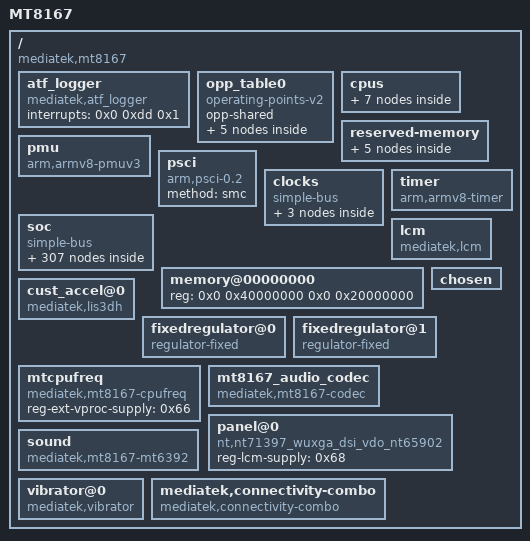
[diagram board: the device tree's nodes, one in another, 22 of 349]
/dts-v1/;

/ {
	model = "MT8167";
	compatible = "mediatek,mt8167";
	interrupt-parent = <0x1>;
	#address-cells = <0x2>;
	#size-cells = <0x2>;

	atf_logger {
		compatible = "mediatek,atf_logger";
		interrupts = <0x0 0xdd 0x1>;
	};

	opp_table0 {
		compatible = "operating-points-v2";
		opp-shared;
		linux,phandle = <0x7>;
		phandle = <0x7>;

		opp00 {
			opp-hz = <0x0 0x23a4c180>;
			opp-microvolt = <0x118c30>;
		};

		opp01 {
			opp-hz = <0x0 0x2c8df1e0>;
			opp-microvolt = <0x118c30>;
		};

		opp02 {
			opp-hz = <0x0 0x3dfd2400>;
			opp-microvolt = <0x124f80>;
		};

		opp03 {
			opp-hz = <0x0 0x47498300>;
			opp-microvolt = <0x1312d0>;
		};

		opp04 {
			opp-hz = <0x0 0x4d7c6d00>;
			opp-microvolt = <0x13d620>;
		};
	};

	cpus {
		#address-cells = <0x1>;
		#size-cells = <0x0>;

		cpu@0 {
			device_type = "cpu";
			compatible = "arm,cortex-a53";
			reg = <0x0>;
			enable-method = "psci";
			cpu-idle-states = <0x2 0x2 0x3 0x3 0x3>;
			clocks = <0x4 0x0 0x5 0x8 0x6 0x0>;
			clock-names = "cpu", "intermediate", "armpll";
			operating-points-v2 = <0x7>;
			clock-frequency = "M|m";
			proc-supply = <0x8>;
			linux,phandle = <0x9>;
			phandle = <0x9>;
		};

		cpu@1 {
			device_type = "cpu";
			compatible = "arm,cortex-a53";
			reg = <0x1>;
			enable-method = "psci";
			cpu-idle-states = <0x2 0x2 0x3 0x3 0x3>;
			clocks = <0x4 0x0 0x5 0x8 0x6 0x0>;
			clock-names = "cpu", "intermediate", "armpll";
			operating-points-v2 = <0x7>;
			clock-frequency = "M|m";
			proc-supply = <0x8>;
			linux,phandle = <0xa>;
			phandle = <0xa>;
		};

		cpu@2 {
			device_type = "cpu";
			compatible = "arm,cortex-a53";
			reg = <0x2>;
			enable-method = "psci";
			cpu-idle-states = <0x2 0x2 0x3 0x3 0x3>;
			clocks = <0x4 0x0 0x5 0x8 0x6 0x0>;
			clock-names = "cpu", "intermediate", "armpll";
			operating-points-v2 = <0x7>;
			clock-frequency = "M|m";
			proc-supply = <0x8>;
			linux,phandle = <0xb>;
			phandle = <0xb>;
		};

		cpu@3 {
			device_type = "cpu";
			compatible = "arm,cortex-a53";
			reg = <0x3>;
			enable-method = "psci";
			cpu-idle-states = <0x2 0x2 0x3 0x3 0x3>;
			clocks = <0x4 0x0 0x5 0x8 0x6 0x0>;
			clock-names = "cpu", "intermediate", "armpll";
			operating-points-v2 = <0x7>;
			clock-frequency = "M|m";
			proc-supply = <0x8>;
			linux,phandle = <0xc>;
			phandle = <0xc>;
		};

		idle-states {
			entry-method = "arm,psci";

			cpu-sleep-0-0 {
				compatible = "arm,idle-state";
				arm,psci-suspend-param = <0x10000>;
				entry-latency-us = <0x258>;
				exit-latency-us = <0x258>;
				min-residency-us = <0x4b0>;
				linux,phandle = <0x3>;
				phandle = <0x3>;
			};

			cluster-sleep-0 {
				compatible = "arm,idle-state";
				arm,psci-suspend-param = <0x2010000>;
				entry-latency-us = <0x320>;
				exit-latency-us = <0x3e8>;
				min-residency-us = <0x7d0>;
				linux,phandle = <0x2>;
				phandle = <0x2>;
			};
		};
	};

	reserved-memory {
		#address-cells = <0x2>;
		#size-cells = <0x2>;
		ranges;

		atf-reserved-memory@43000000 {
			compatible = "mediatek,mt8167-atf-reserved-memory";
			no-map;
			reg = <0x0 0x43000000 0x0 0x30000>;
		};

		ram_console-reserved-memory@44400000 {
			compatible = "mediatek,ram_console";
			reg = <0x0 0x44400000 0x0 0x10000>;
		};

		pstore-reserved-memory@44410000 {
			compatible = "mediatek,pstore";
			reg = <0x0 0x44410000 0x0 0xe0000>;
		};

		minirdump-reserved-memory@444f0000 {
			compatible = "mediatek,minirdump";
			reg = <0x0 0x444f0000 0x0 0x10000>;
		};

		consys-reserve-memory {
			compatible = "mediatek,consys-reserve-memory";
			no-map;
			size = <0x0 0x200000>;
			alignment = <0x0 0x200000>;
		};
	};

	pmu {
		compatible = "arm,armv8-pmuv3";
		interrupts = <0x0 0x4 0x8 0x0 0x5 0x8 0x0 0x6 0x8 0x0 0x7 0x8>;
		interrupt-affinity = <0x9 0xa 0xb 0xc>;
	};

	psci {
		compatible = "arm,psci-0.2";
		method = "smc";
	};

	clocks {
		#address-cells = <0x2>;
		#size-cells = <0x2>;
		compatible = "simple-bus";
		ranges;

		clk26m {
			compatible = "fixed-clock";
			#clock-cells = <0x0>;
			clock-frequency = <0x18cba80>;
		};

		clk32k {
			compatible = "fixed-clock";
			#clock-cells = <0x0>;
			clock-frequency = <0x7d00>;
			linux,phandle = <0xe>;
			phandle = <0xe>;
		};

		dummy26m {
			compatible = "fixed-clock";
			clock-frequency = <0x18cba80>;
			#clock-cells = <0x0>;
		};
	};

	timer {
		compatible = "arm,armv8-timer";
		interrupt-parent = <0xd>;
		interrupts = <0x1 0xd 0xf08 0x1 0xe 0xf08 0x1 0xb 0xf08 0x1 0xa 0xf08>;
		clock-frequency = <0xc65d40>;
	};

	soc {
		#address-cells = <0x2>;
		#size-cells = <0x2>;
		compatible = "simple-bus";
		ranges;

		chipid@08000000 {
			compatible = "mediatek,chipid";
			reg = <0x0 0x8000000 0x0 0x4 0x0 0x8000004 0x0 0x4 0x0 0x8000008 0x0 0x4 0x0 0x800000c 0x0 0x4>;
		};

		topckgen@10000000 {
			compatible = "mediatek,mt8167-topckgen", "syscon";
			reg = <0x0 0x10000000 0x0 0x1000>;
			#clock-cells = <0x1>;
			linux,phandle = <0x5>;
			phandle = <0x5>;
		};

		infracfg@10001000 {
			compatible = "mediatek,mt8167-infracfg", "syscon";
			reg = <0x0 0x10001000 0x0 0x1000>;
			#clock-cells = <0x1>;
			linux,phandle = <0x4>;
			phandle = <0x4>;
		};

		btcvsd@10001000 {
			compatible = "mediatek,audio_bt_cvsd";
			offset = <0xc00 0x2 0xfd0 0xfd4 0xfd8>;
			reg = <0x0 0x10001000 0x0 0x1000 0x0 0x18000000 0x0 0x10000 0x0 0x18080000 0x0 0x8000>;
			interrupts = <0x0 0xc2 0x8>;
		};

		mt_soc_btcvsd_rx_pcm@10001000 {
			compatible = "mediatek,mt_soc_btcvsd_rx_pcm";
		};

		mt_soc_btcvsd_tx_pcm@10001000 {
			compatible = "mediatek,mt_soc_btcvsd_tx_pcm";
		};

		syscfg_pctl_a@10005000 {
			compatible = "mediatek,mt8167-pctl-a-syscfg", "syscon";
			reg = <0x0 0x10005000 0x0 0x1000>;
			linux,phandle = <0xf>;
			phandle = <0xf>;
		};

		toprgu@10007000 {
			compatible = "mediatek,mt8167-wdt", "mediatek,mt6589-wdt";
			reg = <0x0 0x10007000 0x0 0x1000>;
			interrupts = <0x0 0xc6 0x2>;
			#reset-cells = <0x1>;
			linux,phandle = <0x54>;
			phandle = <0x54>;
		};

		timer@10008000 {
			compatible = "mediatek,mt8167-timer", "mediatek,mt6577-timer";
			reg = <0x0 0x10008000 0x0 0x1000>;
			interrupts = <0x0 0x84 0x8>;
			clocks = <0x5 0x32 0xe 0x5 0x5a>;
			clock-names = "clk13m", "clk32k", "bus";
		};

		pinctrl@10005000 {
			compatible = "mediatek,mt8167-pinctrl";
			reg = <0x0 0x1000b000 0x0 0x1000>;
			mediatek,pctl-regmap = <0xf>;
			pins-are-numbered;
			gpio-controller;
			#gpio-cells = <0x2>;
			interrupt-controller;
			#interrupt-cells = <0x2>;
			interrupts = <0x0 0x86 0x4>;
			pinctrl-names = "default";
			pinctrl-0 = <0x10>;
			linux,phandle = <0x12>;
			phandle = <0x12>;

			uart0gpiodefault {
				linux,phandle = <0x17>;
				phandle = <0x17>;
			};

			uart0_rx_set {
				linux,phandle = <0x18>;
				phandle = <0x18>;

				pins_cmd_dat {
					pinmux = <0x3e01>;
				};
			};

			uart0_rx_clear {
				linux,phandle = <0x19>;
				phandle = <0x19>;

				pins_cmd_dat {
					pinmux = <0x3e00>;
					slew-rate = <0x1>;
					output-high;
				};
			};

			uart0_tx_set {
				linux,phandle = <0x1a>;
				phandle = <0x1a>;

				pins_cmd_dat {
					pinmux = <0x3f01>;
				};
			};

			uart0_tx_clear {
				linux,phandle = <0x1b>;
				phandle = <0x1b>;

				pins_cmd_dat {
					pinmux = <0x3f00>;
					slew-rate = <0x1>;
					output-high;
				};
			};

			uart1gpiodefault {
				linux,phandle = <0x1c>;
				phandle = <0x1c>;
			};

			uart1_rx_set {
				linux,phandle = <0x1d>;
				phandle = <0x1d>;

				pins_cmd_dat {
					pinmux = <0x4001>;
				};
			};

			uart1_rx_clear {
				linux,phandle = <0x1e>;
				phandle = <0x1e>;

				pins_cmd_dat {
					pinmux = <0x4000>;
					slew-rate = <0x1>;
					output-high;
				};
			};

			uart1_tx_set {
				linux,phandle = <0x1f>;
				phandle = <0x1f>;

				pins_cmd_dat {
					pinmux = <0x4101>;
				};
			};

			uart1_tx_clear {
				linux,phandle = <0x20>;
				phandle = <0x20>;

				pins_cmd_dat {
					pinmux = <0x4100>;
					slew-rate = <0x1>;
					output-high;
				};
			};

			uart2gpiodefault {
				linux,phandle = <0x21>;
				phandle = <0x21>;
			};

			uart2_rx_set {
				linux,phandle = <0x22>;
				phandle = <0x22>;

				pins_cmd_dat {
					pinmux = <0x2201>;
				};
			};

			uart2_rx_clear {
				linux,phandle = <0x23>;
				phandle = <0x23>;

				pins_cmd_dat {
					pinmux = <0x2200>;
					slew-rate = <0x1>;
					output-high;
				};
			};

			uart2_tx_set {
				linux,phandle = <0x24>;
				phandle = <0x24>;

				pins_cmd_dat {
					pins = <0x2301>;
				};
			};

			uart2_tx_clear {
				linux,phandle = <0x25>;
				phandle = <0x25>;

				pins_cmd_dat {
					pinmux = <0x2300>;
					slew-rate = <0x1>;
					output-high;
				};
			};

			pinconf_default {
				linux,phandle = <0x10>;
				phandle = <0x10>;
			};

			audiodefault {
				linux,phandle = <0x69>;
				phandle = <0x69>;

				pins_extamp_default {
					pins = <0x1700>;
					slew-rate = <0x1>;
					output-low;
				};
			};

			audexampon {
				linux,phandle = <0x6a>;
				phandle = <0x6a>;

				pins_cmd_dat {
					pins = <0x1700>;
					slew-rate = <0x1>;
					output-high;
				};
			};

			audexampoff {
				linux,phandle = <0x6b>;
				phandle = <0x6b>;

				pins_cmd_dat {
					pins = <0x1700>;
					slew-rate = <0x1>;
					output-low;
				};
			};

			audi2s1mode0 {
			};

			audi2s1mode1 {
			};

			pmicclkmode0 {
			};

			pmicclkmode1 {
			};

			camdefault {
				linux,phandle = <0x47>;
				phandle = <0x47>;

				pins_cmd_dat {
					pinmux = <0x5401 0x5501 0x5601 0x5701 0x5801 0x5901 0x5a01 0x5b01 0x5c01 0x5d01>;
				};
			};

			cam_pin_gpio90 {
				linux,phandle = <0x4a>;
				phandle = <0x4a>;
			};

			cam_pin_gpio91 {
				linux,phandle = <0x4b>;
				phandle = <0x4b>;
			};

			cam_pin_gpio92 {
				linux,phandle = <0x4c>;
				phandle = <0x4c>;
			};

			cam_pin_gpio93 {
				linux,phandle = <0x4d>;
				phandle = <0x4d>;
			};

			cam_pin_gpio94 {
				linux,phandle = <0x4e>;
				phandle = <0x4e>;
			};

			cam_pin_gpio95 {
				linux,phandle = <0x4f>;
				phandle = <0x4f>;
			};

			cam_pin_gpio96 {
				linux,phandle = <0x50>;
				phandle = <0x50>;
			};

			cam_pin_gpio97 {
				linux,phandle = <0x51>;
				phandle = <0x51>;
			};

			cam_pin_gpio98 {
				linux,phandle = <0x52>;
				phandle = <0x52>;
			};

			cam_pin_gpio99 {
				linux,phandle = <0x53>;
				phandle = <0x53>;
			};

			cam_pin_mclk {
				linux,phandle = <0x48>;
				phandle = <0x48>;

				pins_cmd_dat {
					pins = <0x6601>;
				};
			};

			cam_pin_pclk {
				linux,phandle = <0x49>;
				phandle = <0x49>;
			};

			default {
				linux,phandle = <0x55>;
				phandle = <0x55>;
			};

			eint0default {
				linux,phandle = <0x5c>;
				phandle = <0x5c>;

				pins_cmd_dat {
					pins = <0x6400>;
					slew-rate = <0x0>;
					bias-disable;
				};
			};

			eint@0 {
				linux,phandle = <0x5d>;
				phandle = <0x5d>;

				pins_cmd_dat {
					pins = <0x6400>;
					slew-rate = <0x0>;
					bias-disable;
				};
			};

			eintoutput0 {
				linux,phandle = <0x5e>;
				phandle = <0x5e>;

				pins_cmd_dat {
					pins = <0x6400>;
					slew-rate = <0x1>;
					output-low;
				};
			};

			eintoutput1 {
				linux,phandle = <0x5f>;
				phandle = <0x5f>;

				pins_cmd_dat {
					pins = <0x6400>;
					slew-rate = <0x1>;
					output-high;
				};
			};

			rstoutput0 {
				linux,phandle = <0x60>;
				phandle = <0x60>;

				pins_cmd_dat {
					pins = <0x6500>;
					slew-rate = <0x1>;
					output-low;
				};
			};

			rstoutput1 {
				linux,phandle = <0x61>;
				phandle = <0x61>;

				pins_cmd_dat {
					pins = <0x6500>;
					slew-rate = <0x1>;
					output-high;
				};
			};

			hwen_high {
				linux,phandle = <0x63>;
				phandle = <0x63>;
			};

			hwen_low {
				linux,phandle = <0x64>;
				phandle = <0x64>;
			};

			gpslna@0 {
				linux,phandle = <0x56>;
				phandle = <0x56>;
			};

			gpslna@1 {
				linux,phandle = <0x57>;
				phandle = <0x57>;
			};

			gpslna@2 {
				linux,phandle = <0x58>;
				phandle = <0x58>;
			};

			hdmi_pins_default {
				linux,phandle = <0x3e>;
				phandle = <0x3e>;
			};

			hdmi_pins_hpd {
				linux,phandle = <0x3f>;
				phandle = <0x3f>;
			};

			i2c0@0 {
				linux,phandle = <0x26>;
				phandle = <0x26>;

				pins1 {
					pinmux = <0x3a01 0x3b01>;
					bias-disable;
				};
			};

			i2c1@0 {
				linux,phandle = <0x27>;
				phandle = <0x27>;

				pins1 {
					pinmux = <0x3401 0x3501>;
					bias-disable;
				};
			};

			i2c2@0 {
				linux,phandle = <0x28>;
				phandle = <0x28>;

				pins1 {
					pinmux = <0x3c01 0x3d01>;
					bias-disable;
				};
			};

			mmc0default {
				linux,phandle = <0x31>;
				phandle = <0x31>;

				pins_cmd_dat {
					pinmux = <0x7801 0x7701 0x7601 0x7501 0x7101 0x7001 0x6f01 0x6e01 0x7301>;
					input-enable;
					bias-pull-up;
				};

				pins_clk {
					pinmux = <0x7401>;
					bias-pull-down;
				};

				pins_rst {
					pinmux = <0x7201>;
					bias-pull-up;
				};
			};

			mmc0@0 {
				linux,phandle = <0x32>;
				phandle = <0x32>;

				pins_cmd_dat {
					pinmux = <0x7801 0x7701 0x7601 0x7501 0x7101 0x7001 0x6f01 0x6e01 0x7301>;
					input-enable;
					drive-strength = <0x6>;
					bias-pull-up = <0x65>;
				};

				pins_clk {
					pinmux = <0x7401>;
					drive-strength = <0x8>;
					bias-pull-down = <0x66>;
				};

				pins_rst {
					pinmux = <0x7201>;
					bias-pull-up;
				};
			};

			mmc1default {
				linux,phandle = <0x35>;
				phandle = <0x35>;

				pins_cmd_dat {
					pinmux = <0x6a01 0x6b01 0x6c01 0x6d01 0x6801>;
					input-enable;
					drive-strength = <0x6>;
					bias-pull-up = <0x65>;
				};

				pins_clk {
					pinmux = <0x6901>;
					drive-strength = <0x6>;
					bias-pull-down = <0x66>;
				};

				pins_insert {
					pinmux = <0x1400>;
					bias-pull-up;
				};
			};

			mmc1@0 {
				linux,phandle = <0x36>;
				phandle = <0x36>;

				pins_cmd_dat {
					pinmux = <0x6a01 0x6b01 0x6c01 0x6d01 0x6801>;
					input-enable;
					drive-strength = <0x6>;
					bias-pull-up = <0x65>;
				};

				pins_clk {
					pinmux = <0x6901>;
					drive-strength = <0x8>;
					bias-pull-down = <0x66>;
				};
			};

			mmc2default {
				linux,phandle = <0x39>;
				phandle = <0x39>;

				pins_cmd_dat {
					pinmux = <0x4601 0x4701 0x4801 0x4901 0x4401>;
					input-enable;
					drive-strength = <0x8>;
					bias-pull-up = <0x66>;
				};

				pins_clk {
					pinmux = <0x4501>;
					drive-strength = <0x8>;
					bias-pull-down = <0x66>;
				};
			};

			cfg_pmu_en_pull_dis {
				linux,phandle = <0x6c>;
				phandle = <0x6c>;

				combo_pins {
					pins = <0x200>;
					bias-disable;
				};
			};

			cfg_pmu_en_in_pulldown {
				linux,phandle = <0x6d>;
				phandle = <0x6d>;

				combo_pins {
					pins = <0x200>;
					bias-pull-down;
				};
			};

			cfg_rst_pull_dis {
				linux,phandle = <0x6e>;
				phandle = <0x6e>;

				combo_pins {
					pins = <0x700>;
					bias-disable;
				};
			};

			cfg_wifi_eint_in_pull_dis {
				linux,phandle = <0x6f>;
				phandle = <0x6f>;

				combo_pins {
					pins = <0x500>;
					slew-rate = <0x0>;
					bias-disable;
				};
			};

			cfg_wifi_eint_in_pullup {
				linux,phandle = <0x70>;
				phandle = <0x70>;

				combo_pins {
					pins = <0x500>;
					slew-rate = <0x0>;
					bias-pull-up = <0x0>;
				};
			};

			cfg_pcm_daiclk_pull_dis {
				linux,phandle = <0x71>;
				phandle = <0x71>;

				combo_pins {
					pins = <0x2401>;
					bias-disable;
				};
			};

			cfg_pcm_daipcmin_pull_dis {
				linux,phandle = <0x72>;
				phandle = <0x72>;

				combo_pins {
					pins = <0x2601>;
					bias-disable;
				};
			};

			cfg_pcm_daipcmout_pull_dis {
				linux,phandle = <0x73>;
				phandle = <0x73>;

				combo_pins {
					pins = <0x2701>;
					bias-disable;
				};
			};

			cfg_pcm_daisync_pull_dis {
				linux,phandle = <0x74>;
				phandle = <0x74>;

				combo_pins {
					pins = <0x2501>;
					bias-disable;
				};
			};

			cfg_gps_lna_pull_dis {
				linux,phandle = <0x75>;
				phandle = <0x75>;

				combo_pins {
					pins = <0x300>;
					bias-disable;
				};
			};

			drvvbus_init {
				linux,phandle = <0x2c>;
				phandle = <0x2c>;

				pins_cmd_dat {
					pins = <0x4400>;
					output-low;
				};
			};

			drvvbus_high {
				linux,phandle = <0x2e>;
				phandle = <0x2e>;

				pins_cmd_dat {
					pins = <0x4400>;
					slew-rate = <0x1>;
					output-high;
				};
			};

			drvvbus_low {
				linux,phandle = <0x2d>;
				phandle = <0x2d>;

				pins_cmd_dat {
					pins = <0x4400>;
					slew-rate = <0x1>;
					output-low;
				};
			};

			iddig_irq_init {
				linux,phandle = <0x2b>;
				phandle = <0x2b>;

				pins_cmd_dat {
					pins = <0x2902>;
					slew-rate = <0x0>;
					bias-pull-up = <0x0>;
				};
			};

			vbus_init {
				linux,phandle = <0x3a>;
				phandle = <0x3a>;

				pins_cmd_dat {
					pins = <0x1800>;
					output-high;
				};
			};

			vbus_high {
				linux,phandle = <0x3c>;
				phandle = <0x3c>;

				pins_cmd_dat {
					pins = <0x1800>;
					slew-rate = <0x1>;
					output-high;
				};
			};

			vbus_low {
				linux,phandle = <0x3b>;
				phandle = <0x3b>;

				pins_cmd_dat {
					pins = <0x1800>;
					slew-rate = <0x1>;
					output-low;
				};
			};

			iddig_irq {
				linux,phandle = <0x3d>;
				phandle = <0x3d>;

				pins_cmd_dat {
					pins = <0x2800>;
					slew-rate = <0x0>;
					bias-pull-up = <0x0>;
				};
			};
		};

		dramco@10207000 {
			compatible = "mediatek,mt8167-dramco";
			reg = <0x0 0x10207000 0x0 0x1000>;
		};

		scpsys@10006000 {
			compatible = "mediatek,mt8167-scpsys", "syscon";
			#power-domain-cells = <0x1>;
			reg = <0x0 0x10006000 0x0 0x1000>;
			interrupts = <0x0 0x80 0x8 0x0 0x81 0x8 0x0 0x82 0x8 0x0 0x83 0x8>;
			infracfg = <0x4>;
			clocks = <0x5 0x82 0x5 0x83 0x5 0x42 0x5 0x7f>;
			clock-names = "axi_mfg", "mfg", "mm", "vdec";
			mediatek,pwrap-regmap = <0x11>;
			linux,phandle = <0x30>;
			phandle = <0x30>;
		};

		hacc@1000a000 {
			compatible = "mediatek,hacc";
			reg = <0x0 0x1000a000 0x0 0x1000>;
			clocks = <0x5 0x57 0x5 0x66>;
			clock-names = "main", "second";
		};

		pwrap@1000f000 {
			compatible = "mediatek,mt8167-pwrap";
			reg = <0x0 0x1000f000 0x0 0x1000>;
			reg-names = "pwrap";
			interrupts = <0x0 0xcc 0x8>;
			clocks = <0x5 0x5e 0x5 0x56>;
			clock-names = "spi", "wrap";
			status = "okay";
			linux,phandle = <0x11>;
			phandle = <0x11>;

			mt6392 {
				compatible = "mediatek,mt6392";
				mediatek,system-power-controller;
				interrupt-parent = <0x12>;
				interrupts = <0x1c 0x4>;
				interrupt-controller;
				#interrupt-cells = <0x2>;
				linux,phandle = <0x62>;
				phandle = <0x62>;

				mt6392keys {
					compatible = "mediatek,mt6392-keys";
					mediatek,pwrkey-code = <0x74>;
					mediatek,homekey-code = <0x0>;
					mediatek,long-press-mode = <0x1>;
					mediatek,long-press-duration = <0x3>;
				};

				mt6392pmic {
					compatible = "mediatek,mt6392-pmic";
				};

				mt6392regulator {
					compatible = "mediatek,mt6392-regulator";

					buck_vproc {
						regulator-name = "vproc";
						regulator-min-microvolt = <0xaae60>;
						regulator-max-microvolt = <0x149970>;
						regulator-ramp-delay = <0x30d4>;
						regulator-always-on;
						regulator-boot-on;
						linux,phandle = <0x8>;
						phandle = <0x8>;
					};

					buck_vsys {
						regulator-name = "vsys";
						regulator-min-microvolt = <0x155cc0>;
						regulator-max-microvolt = <0x2d95ec>;
						regulator-ramp-delay = <0x61a8>;
						regulator-always-on;
						regulator-boot-on;
					};

					buck_vcore {
						regulator-name = "vcore";
						regulator-min-microvolt = <0xaae60>;
						regulator-max-microvolt = <0x149970>;
						regulator-ramp-delay = <0x30d4>;
						regulator-always-on;
						regulator-boot-on;
						linux,phandle = <0x2a>;
						phandle = <0x2a>;
					};

					ldo_vxo22 {
						regulator-name = "vxo22";
						regulator-min-microvolt = <0x2191c0>;
						regulator-max-microvolt = <0x2191c0>;
						regulator-enable-ramp-delay = <0x6e>;
						regulator-always-on;
						regulator-boot-on;
					};

					ldo_vaud22 {
						regulator-name = "vaud22";
						regulator-min-microvolt = <0x1b7740>;
						regulator-max-microvolt = <0x2191c0>;
						regulator-enable-ramp-delay = <0x108>;
						regulator-always-on;
						regulator-boot-on;
					};

					ldo_vcama {
						regulator-name = "vcama";
						regulator-min-microvolt = <0x2ab980>;
						regulator-max-microvolt = <0x2ab980>;
						regulator-enable-ramp-delay = <0x108>;
						linux,phandle = <0x43>;
						phandle = <0x43>;
					};

					ldo_vaud28 {
						regulator-name = "vaud28";
						regulator-min-microvolt = <0x2ab980>;
						regulator-max-microvolt = <0x2ab980>;
						regulator-enable-ramp-delay = <0x108>;
						regulator-always-on;
						regulator-boot-on;
					};

					ldo_vadc18 {
						regulator-name = "vadc18";
						regulator-min-microvolt = <0x1b7740>;
						regulator-max-microvolt = <0x1b7740>;
						regulator-enable-ramp-delay = <0x108>;
						regulator-always-on;
						regulator-boot-on;
					};

					ldo_vcn35 {
						regulator-name = "vcn35";
						regulator-min-microvolt = <0x325aa0>;
						regulator-max-microvolt = <0x36ee80>;
						regulator-enable-ramp-delay = <0x108>;
						linux,phandle = <0x5a>;
						phandle = <0x5a>;
					};

					ldo_vio28 {
						regulator-name = "vio28";
						regulator-min-microvolt = <0x2ab980>;
						regulator-max-microvolt = <0x2ab980>;
						regulator-enable-ramp-delay = <0x108>;
						regulator-always-on;
						regulator-boot-on;
					};

					ldo_vusb {
						regulator-name = "vusb";
						regulator-min-microvolt = <0x325aa0>;
						regulator-max-microvolt = <0x325aa0>;
						regulator-enable-ramp-delay = <0x108>;
						regulator-always-on;
						regulator-boot-on;
						linux,phandle = <0x2f>;
						phandle = <0x2f>;
					};

					ldo_vmc {
						regulator-name = "vmc";
						regulator-min-microvolt = <0x1b7740>;
						regulator-max-microvolt = <0x325aa0>;
						regulator-enable-ramp-delay = <0x108>;
						regulator-boot-on;
						linux,phandle = <0x38>;
						phandle = <0x38>;
					};

					ldo_vmch {
						regulator-name = "vmch";
						regulator-min-microvolt = <0x2dc6c0>;
						regulator-max-microvolt = <0x325aa0>;
						regulator-enable-ramp-delay = <0x108>;
						regulator-boot-on;
						linux,phandle = <0x37>;
						phandle = <0x37>;
					};

					ldo_vemc3v3 {
						regulator-name = "vemc3v3";
						regulator-min-microvolt = <0x2dc6c0>;
						regulator-max-microvolt = <0x325aa0>;
						regulator-enable-ramp-delay = <0x108>;
						regulator-boot-on;
						linux,phandle = <0x33>;
						phandle = <0x33>;
					};

					ldo_vgp1 {
						regulator-name = "vgp1";
						regulator-min-microvolt = <0x124f80>;
						regulator-max-microvolt = <0x325aa0>;
						regulator-enable-ramp-delay = <0x108>;
						linux,phandle = <0x5b>;
						phandle = <0x5b>;
					};

					ldo_vgp2 {
						regulator-name = "vgp2";
						regulator-min-microvolt = <0x124f80>;
						regulator-max-microvolt = <0x325aa0>;
						regulator-enable-ramp-delay = <0x108>;
						linux,phandle = <0x68>;
						phandle = <0x68>;
					};

					ldo_vcn18 {
						regulator-name = "vcn18";
						regulator-min-microvolt = <0x1b7740>;
						regulator-max-microvolt = <0x1b7740>;
						regulator-enable-ramp-delay = <0x108>;
						linux,phandle = <0x59>;
						phandle = <0x59>;
					};

					ldo_vcamaf {
						regulator-name = "vcamaf";
						regulator-min-microvolt = <0x124f80>;
						regulator-max-microvolt = <0x325aa0>;
						regulator-enable-ramp-delay = <0x108>;
						linux,phandle = <0x46>;
						phandle = <0x46>;
					};

					ldo_vm {
						regulator-name = "vm";
						regulator-min-microvolt = <0x12ebc0>;
						regulator-max-microvolt = <0x1535b0>;
						regulator-enable-ramp-delay = <0x108>;
					};

					ldo_vio18 {
						regulator-name = "vio18";
						regulator-min-microvolt = <0x1b7740>;
						regulator-max-microvolt = <0x1b7740>;
						regulator-enable-ramp-delay = <0x108>;
						regulator-always-on;
						regulator-boot-on;
						linux,phandle = <0x34>;
						phandle = <0x34>;
					};

					ldo_vcamd {
						regulator-name = "vcamd";
						regulator-min-microvolt = <0x124f80>;
						regulator-max-microvolt = <0x1b7740>;
						regulator-enable-ramp-delay = <0x108>;
						linux,phandle = <0x44>;
						phandle = <0x44>;
					};

					ldo_vcamio {
						regulator-name = "vcamio";
						regulator-min-microvolt = <0x1b7740>;
						regulator-max-microvolt = <0x1b7740>;
						regulator-enable-ramp-delay = <0x108>;
						linux,phandle = <0x45>;
						phandle = <0x45>;
					};

					ldo_vm25 {
						regulator-name = "vm25";
						regulator-min-microvolt = <0x2625a0>;
						regulator-max-microvolt = <0x2625a0>;
						regulator-enable-ramp-delay = <0x108>;
					};

					ldo_vefuse {
						regulator-name = "vefuse";
						regulator-min-microvolt = <0x1b7740>;
						regulator-max-microvolt = <0x1e8480>;
						regulator-enable-ramp-delay = <0x108>;
					};
				};

				pinctrl@c000 {
					compatible = "mediatek,mt6392-pinctrl";
					pins-are-numbered;
					gpio-controller;
					#gpio-cells = <0x2>;
				};

				typec {
					compatible = "mediatek,mt6392-typec";
					status = "disabled";
				};
			};
		};

		devapc_ao@10010000 {
			compatible = "mediatek,mt8167-devapc_ao";
			reg = <0x0 0x10010000 0x0 0x1000>;
		};

		keypad@10002000 {
			compatible = "mediatek,mt8167-keypad";
			reg = <0x0 0x10002000 0x0 0x1000>;
			interrupts = <0x0 0x95 0x2>;
			mediatek,kpd-key-debounce = <0x400>;
			mediatek,kpd-sw-pwrkey = <0x74>;
			mediatek,kpd-hw-pwrkey = <0x8>;
			mediatek,kpd-sw-rstkey = <0x0>;
			mediatek,kpd-hw-rstkey = <0x11>;
			mediatek,kpd-use-extend-type = <0x0>;
			mediatek,kpd-hw-map-num = <0x48>;
			mediatek,kpd-hw-init-map = <0x72 0x73 0x0 0x0 0x0 0x0 0x0 0x0 0x0 0x0 0x0 0x0 0x0 0x0 0x0 0x0 0x0 0x0 0x0 0x0 0x0 0x0 0x0 0x0 0x0 0x0 0x0 0x0 0x0 0x0 0x0 0x0 0x0 0x0 0x0 0x0 0x0 0x0 0x0 0x0 0x0 0x0 0x0 0x0 0x0 0x0 0x0 0x0 0x0 0x0 0x0 0x0 0x0 0x0 0x0 0x0 0x0 0x0 0x0 0x0 0x0 0x0 0x0 0x0 0x0 0x0 0x0 0x0 0x0 0x0 0x0 0x0>;
			mediatek,kpd-pwrkey-eint-gpio = <0x0>;
			mediatek,kpd-pwkey-gpio-din = <0x0>;
			mediatek,kpd-hw-dl-key0 = <0x0>;
			mediatek,kpd-hw-dl-key1 = <0x11>;
			mediatek,kpd-hw-dl-key2 = <0x8>;
			mediatek,kpd-hw-recovery-key = <0x11>;
			mediatek,kpd-hw-factory-key = <0x0>;
		};

		apmixedsys@10018000 {
			compatible = "mediatek,mt8167-apmixedsys", "syscon";
			reg = <0x0 0x10018000 0x0 0x710>;
			#clock-cells = <0x1>;
			linux,phandle = <0x6>;
			phandle = <0x6>;
		};

		fhctl@10018f00 {
			compatible = "mediatek,mt8167-fhctl";
			reg = <0x0 0x10018f00 0x0 0x100>;
		};

		accdet@1001b000 {
			compatible = "mediatek,mt8167-accdet";
			reg = <0x0 0x1001b000 0x0 0x1000>;
			status = "okay";
			mediatek,apmixedsys-regmap = <0x6>;
			interrupts-extended = <0x1 0x0 0x98 0x8 0x12 0x13 0x8>;
			interrupts = <0x13 0x8>;
			eint-debounce = <0x3e800>;
			accdet-gpio = <0x12 0x13 0x0>;
			accdet-mic-vol = <0x0>;
			headset-mode-setting = <0x500 0x500 0x1 0x1f0 0x800 0x800 0x20>;
			accdet-plugout-debounce = <0x14>;
			accdet-mic-mode = <0x1>;
		};

		mcucfg@10200000 {
			compatible = "mediatek,mt8167-mcucfg", "mediatek,mcucfg", "syscon";
			reg = <0x0 0x10200000 0x0 0x2000>;
		};

		intpol-controller@10200620 {
			compatible = "mediatek,mt8167-sysirq", "mediatek,mt6577-sysirq";
			interrupt-controller;
			#interrupt-cells = <0x3>;
			interrupt-parent = <0xd>;
			reg = <0x0 0x10200620 0x0 0x20>;
			linux,phandle = <0x1>;
			phandle = <0x1>;
		};

		emi@10205000 {
			compatible = "mediatek,mt8167-emi", "mediatek,emi";
			reg = <0x0 0x10205000 0x0 0x1000>;
			interrupts = <0x0 0x74 0x4>;
		};

		m4u@10203000 {
			cell-index = <0x0>;
			compatible = "mediatek,mt8167-m4u";
			reg = <0x0 0x10203000 0x0 0x1000>;
			mediatek,larbs = <0x13 0x14 0x15>;
			interrupts = <0x0 0x79 0x8>;
			#iommu-cells = <0x1>;
			linux,phandle = <0x65>;
			phandle = <0x65>;
		};

		sys_cirq@10202000 {
			compatible = "mediatek,mt8167-sys_cirq", "mediatek,mt6735-sys_cirq", "mediatek,sys_cirq";
			reg = <0x0 0x10202000 0x0 0x1000>;
			interrupts = <0x0 0xda 0x8>;
			mediatek,cirq_num = <0x93>;
			mediatek,spi_start_offset = <0x48>;
		};

		devapc@10204000 {
			compatible = "mediatek,mt8167-devapc";
			reg = <0x0 0x10204000 0x0 0x1000>;
			interrupts = <0x0 0x72 0x8>;
		};

		systracker@1020b000 {
			compatible = "mediatek,bus_dbg-v2";
			reg = <0x0 0x1020b000 0x0 0x1000>;
			interrupts = <0x0 0x7b 0x8>;
		};

		dramc_nao@10206000 {
			compatible = "mediatek,mt8167-dramc_nao", "mediatek,dramc_nao";
			reg = <0x0 0x10206000 0x0 0x1000>;
		};

		xo@10210000 {
			compatible = "mediatek,mt8167-xo";
			reg = <0x0 0x10210000 0x0 0x1000>;
			clocks = <0x5 0x7a 0x5 0x8c>;
			clock-names = "bsi", "rgbsi";
		};

		ddrphy@10211000 {
			compatible = "mediatek,mt8167-ddrphy", "mediatek,ddrphy";
			reg = <0x0 0x10211000 0x0 0x1000>;
		};

		gce@1020a000 {
			compatible = "mediatek,mt8167-gce";
			reg = <0x0 0x1020a000 0x0 0x1000>;
			interrupts = <0x0 0x7d 0x8 0x0 0x7e 0x8>;
			disp_mutex_reg = <0x14015000 0x1000>;
			g3d_config_base = <0x13000000 0x0 0xffff0000>;
			mmsys_config_base = <0x14000000 0x1 0xffff0000>;
			disp_dither_base = <0x14010000 0x2 0xffff0000>;
			mm_na_base = <0x14020000 0x3 0xffff0000>;
			imgsys_base = <0x15000000 0x4 0xffff0000>;
			vdec_gcon_base = <0x16000000 0x5 0xffff0000>;
			venc_gcon_base = <0x17000000 0x6 0xffff0000>;
			conn_peri_base = <0x18000000 0x7 0xffff0000>;
			topckgen_base = <0x10000000 0x8 0xffff0000>;
			kp_base = <0x10010000 0x9 0xffff0000>;
			scp_sram_base = <0x10020000 0xa 0xffff0000>;
			infra_na3_base = <0x10030000 0xb 0xffff0000>;
			infra_na4_base = <0x10040000 0xc 0xffff0000>;
			scp_base = <0x10050000 0xd 0xffff0000>;
			mcucfg_base = <0x10200000 0xe 0xffff0000>;
			gcpu_base = <0x1020d000 0xf 0xffff0000>;
			usb0_base = <0x11200000 0x10 0xffff0000>;
			usb_sif_base = <0x11210000 0x11 0xffff0000>;
			audio_base = <0x11220000 0x12 0xffff0000>;
			msdc0_base = <0x11230000 0x13 0xffff0000>;
			msdc1_base = <0x11240000 0x14 0xffff0000>;
			msdc2_base = <0x11250000 0x15 0xffff0000>;
			msdc3_base = <0x11260000 0x16 0xffff0000>;
			pwm_sw_base = <0x1100f000 0x63 0xfffff000>;
			mdp_rdma0_sof = <0x0>;
			mdp_rsz0_sof = <0x1>;
			mdp_rsz1_sof = <0x2>;
			mdp_tdshp_sof = <0x3>;
			mdp_wdma_sof = <0x4>;
			mdp_wrot_sof = <0x5>;
			disp_ovl0_sof = <0x6>;
			disp_rdma0_sof = <0x8>;
			disp_rdma1_sof = <0x9>;
			disp_wdma0_sof = <0xa>;
			disp_ccorr_sof = <0xb>;
			disp_color_sof = <0xc>;
			disp_aal_sof = <0xd>;
			disp_gamma_sof = <0xe>;
			disp_dither_sof = <0xf>;
			disp_ufoe_sof = <0x10>;
			disp_pwm0_sof = <0x11>;
			mdp_rdma0_frame_done = <0x12>;
			mdp_rsz0_frame_done = <0x13>;
			mdp_rsz1_frame_done = <0x14>;
			mdp_tdshp_frame_done = <0x15>;
			mdp_wdma_frame_done = <0x16>;
			mdp_wrot_write_frame_done = <0x17>;
			mdp_wrot_read_frame_done = <0x18>;
			disp_ovl0_frame_done = <0x19>;
			disp_rdma0_frame_done = <0x1b>;
			disp_rdma1_frame_done = <0x1c>;
			disp_wdma0_frame_done = <0x1d>;
			disp_ccorr_frame_done = <0x1e>;
			disp_color_frame_done = <0x1f>;
			disp_aal_frame_done = <0x20>;
			disp_gamma_frame_done = <0x21>;
			disp_dither_frame_done = <0x22>;
			disp_ufoe_frame_done = <0x23>;
			disp_dpi0_frame_done = <0x24>;
			disp_dpi1_frame_done = <0x25>;
			stream_done_0 = <0x26>;
			stream_done_1 = <0x27>;
			stream_done_2 = <0x28>;
			stream_done_3 = <0x29>;
			stream_done_4 = <0x2a>;
			stream_done_5 = <0x2b>;
			stream_done_6 = <0x2c>;
			stream_done_7 = <0x2d>;
			stream_done_8 = <0x2e>;
			stream_done_9 = <0x2f>;
			buf_underrun_event_0 = <0x30>;
			buf_underrun_event_1 = <0x31>;
			isp_frame_done_p2_1 = <0x42>;
			isp_frame_done_p2_0 = <0x43>;
			seninf_cam0_fifo_full = <0x49>;
			apxgpt2_count = <0x10008028>;
			clocks = <0x5 0x64 0x16 0x0 0x16 0x1 0x16 0x2 0x16 0x3 0x16 0x4 0x16 0x5 0x16 0x6 0x16 0x8 0x16 0x7>;
			clock-names = "MT_CG_INFRA_GCE", "MT_CG_DISP0_SMI_COMMON", "MT_CG_DISP0_SMI_LARB0", "MT_CG_DISP0_CAM_MDP", "MT_CG_DISP0_MDP_RDMA", "MT_CG_DISP0_MDP_RSZ0", "MT_CG_DISP0_MDP_RSZ1", "MT_CG_DISP0_MDP_TDSHP", "MT_CG_DISP0_MDP_WROT", "MT_CG_DISP0_MDP_WDMA";
		};

		interrupt-controller@10310000 {
			compatible = "arm,gic-400";
			interrupt-controller;
			#interrupt-cells = <0x3>;
			interrupt-parent = <0xd>;
			reg = <0x0 0x10310000 0x0 0x1000 0x0 0x10320000 0x0 0x1000 0x0 0x10340000 0x0 0x2000 0x0 0x10360000 0x0 0x2000>;
			interrupts = <0x1 0x9 0xf04>;
			linux,phandle = <0xd>;
			phandle = <0xd>;
		};

		btif_tx@11000380 {
			compatible = "mediatek,btif_tx";
			reg = <0x0 0x11000380 0x0 0x80>;
			interrupts = <0x0 0x5e 0x8>;
		};

		btif_rx@11000400 {
			compatible = "mediatek,btif_rx";
			reg = <0x0 0x11000400 0x0 0x80>;
			interrupts = <0x0 0x5f 0x8>;
		};

		nfi@11001000 {
			compatible = "mediatek,mt8167-nfi";
			reg = <0x0 0x11001000 0x0 0x1000>;
			interrupts = <0x0 0x57 0x8>;
			clocks = <0x5 0x63 0x5 0x49 0x5 0x48 0x5 0x8e 0x5 0x55 0x5 0x3a 0x5 0xad 0x5 0xac 0x5 0xce 0x5 0xcd 0x5 0xa1 0x5 0x31 0x5 0x9 0x5 0x11 0x5 0xf 0x5 0x15 0x5 0xa 0x5 0x12 0x5 0x10>;
			clock-names = "nfi_hclk", "nfiecc_bclk", "nfi_bclk", "nfi_rgecc", "nfi_2xclk", "nfi_1xclk", "nfi_1xpad_sel", "nfi_2xpad_sel", "nfiecc_sel", "nfiecc_csw_sel", "infra_ahb", "clk_26m", "main_d4", "main_d5", "main_d6", "main_d7", "main_d8", "main_d10", "main_d12";
			status = "disabled";
		};

		nfiecc@11002000 {
			compatible = "mediatek,mt8167-nfiecc";
			reg = <0x0 0x11002000 0x0 0x1000>;
			interrupts = <0x0 0x56 0x8>;
			status = "disabled";
		};

		auxadc@11003000 {
			compatible = "mediatek,mt8167-auxadc";
			reg = <0x0 0x11003000 0x0 0x1000>;
			interrupts = <0x0 0x4b 0x2>;
			clocks = <0x5 0x5f 0x5 0x47 0x5 0x51 0x5 0x60>;
			clock-names = "auxadc-main", "auxadc1", "auxadc2", "auxadc-tp";
			linux,phandle = <0x29>;
			phandle = <0x29>;
		};

		uart0@11005000 {
			cell-index = <0x0>;
			compatible = "mediatek,mt8167-uart";
			reg = <0x0 0x11005000 0x0 0x1000 0x0 0x11000480 0x0 0x80 0x0 0x11000500 0x0 0x80>;
			interrupts = <0x0 0x54 0x8 0x0 0x60 0x8 0x0 0x61 0x8>;
			clock-frequency = <0x18cba80>;
			clock-div = <0x1>;
			clocks = <0x5 0x4c 0x5 0x44>;
			clock-names = "uart0-main", "uart-apdma";
			pinctrl-names = "uart0_gpio_default", "uart0_rx_set", "uart0_rx_clear", "uart0_tx_set", "uart0_tx_clear";
			pinctrl-0 = <0x17>;
			pinctrl-1 = <0x18>;
			pinctrl-2 = <0x19>;
			pinctrl-3 = <0x1a>;
			pinctrl-4 = <0x1b>;
			status = "okay";
		};

		uart1@11006000 {
			cell-index = <0x1>;
			compatible = "mediatek,mt8167-uart", "mediatek,mt6577-uart";
			reg = <0x0 0x11006000 0x0 0x1000 0x0 0x11000580 0x0 0x80 0x0 0x11000600 0x0 0x80>;
			interrupts = <0x0 0x55 0x8 0x0 0x62 0x8 0x0 0x63 0x8>;
			clock-frequency = <0x18cba80>;
			clock-div = <0x1>;
			clocks = <0x5 0x4d>;
			clock-names = "uart1-main";
			pinctrl-names = "uart1_gpio_default", "uart1_rx_set", "uart1_rx_clear", "uart1_tx_set", "uart1_tx_clear";
			pinctrl-0 = <0x1c>;
			pinctrl-1 = <0x1d>;
			pinctrl-2 = <0x1e>;
			pinctrl-3 = <0x1f>;
			pinctrl-4 = <0x20>;
			status = "okay";
		};

		uart2@11007000 {
			cell-index = <0x2>;
			compatible = "mediatek,mt8167-uart";
			reg = <0x0 0x11007000 0x0 0x1000 0x0 0x11000980 0x0 0x80 0x0 0x11000a00 0x0 0x80>;
			interrupts = <0x0 0xd4 0x8 0x0 0x64 0x8 0x0 0x65 0x8>;
			clock-frequency = <0x18cba80>;
			clock-div = <0x1>;
			clocks = <0x5 0x79>;
			clock-names = "uart2-main";
			pinctrl-names = "uart2_gpio_default", "uart2_rx_set", "uart2_rx_clear", "uart2_tx_set", "uart2_tx_clear";
			pinctrl-0 = <0x21>;
			pinctrl-1 = <0x22>;
			pinctrl-2 = <0x23>;
			pinctrl-3 = <0x24>;
			pinctrl-4 = <0x25>;
			status = "disabled";
		};

		pwm@11008000 {
			compatible = "mediatek,mt8167-pwm";
			reg = <0x0 0x11008000 0x0 0x1000>;
			interrupts = <0x0 0x4c 0x8>;
			clocks = <0x5 0x69 0x5 0x6a 0x5 0x6b 0x5 0x6c 0x5 0x6d 0x5 0x4b 0x5 0x68>;
			clock-names = "PWM1-main", "PWM2-main", "PWM3-main", "PWM4-main", "PWM5-main", "PWM-HCLK-main", "PWM-main";
		};

		i2c@11009000 {
			compatible = "mediatek,mt8167-i2c";
			reg = <0x0 0x11009000 0x0 0x90 0x0 0x11000180 0x0 0x80>;
			interrupts = <0x0 0x50 0x8>;
			clocks = <0x5 0x39 0x4 0x2 0x5 0x45 0x5 0x44>;
			clock-names = "main-source", "main-sel", "main", "dma";
			#address-cells = <0x1>;
			#size-cells = <0x0>;
			status = "okay";
			clock-div = <0x2>;
			pinctrl-names = "default";
			pinctrl-0 = <0x26>;

			lp8557_led@2c {
				compatible = "ti,lp8557-led";
				reg = <0x2c>;
			};

			cap_touch@38 {
				compatible = "mediatek,cap_touch";
				reg = <0x38>;
				interrupt-parent = <0x12>;
				interrupts = <0x64 0x2>;
				int-gpio = <0x12 0x64 0x0>;
				rst-gpio = <0x12 0x65 0x0>;
			};

			strobe_main@63 {
				compatible = "mediatek,strobe_main";
				reg = <0x63>;
			};
		};

		i2c@1100a000 {
			compatible = "mediatek,mt8167-i2c";
			reg = <0x0 0x1100a000 0x0 0x90 0x0 0x11000200 0x0 0x80>;
			interrupts = <0x0 0x51 0x8>;
			clocks = <0x5 0x39 0x4 0x3 0x5 0x46 0x5 0x44>;
			clock-names = "main-source", "main-sel", "main", "dma";
			#address-cells = <0x1>;
			#size-cells = <0x0>;
			status = "okay";
			clock-div = <0x2>;
			pinctrl-names = "default";
			pinctrl-0 = <0x27>;

			gsensor@19 {
				compatible = "mediatek,gsensor";
				reg = <0x19>;
			};

			sym827@60 {
				compatible = "silergy,sym827-regulator";
				reg = <0x60>;
				regulator-name = "vproc";
				regulator-min-microvolt = <0x927c0>;
				regulator-max-microvolt = <0x152bec>;
				regulator-enable-ramp-delay = <0x190>;
				regulator-ramp-delay = <0x208d>;
				regulator-always-on;
				vsel-gpio = <0x12 0x22 0x0>;
				linux,phandle = <0x66>;
				phandle = <0x66>;
			};

			bq24296@6b {
				compatible = "ti,bq24296";
				reg = <0x6b>;
			};
		};

		i2c@1100b000 {
			compatible = "mediatek,mt8167-i2c";
			reg = <0x0 0x1100b000 0x0 0x90 0x0 0x11000280 0x0 0x80>;
			interrupts = <0x0 0x52 0x8>;
			clocks = <0x5 0x39 0x4 0x4 0x5 0x52 0x5 0x44>;
			clock-names = "main-source", "main-sel", "main", "dma";
			#address-cells = <0x1>;
			#size-cells = <0x0>;
			status = "okay";
			clock-div = <0x2>;
			clock-frequency = <0x61a80>;
			pinctrl-names = "default";
			pinctrl-0 = <0x28>;

			camera_main_af@0c {
				compatible = "mediatek,camera_main_af";
				reg = <0xc>;
			};

			kd_camera_hw2@30 {
				compatible = "mediatek,camera_sub";
				reg = <0x30>;
			};

			kd_camera_hw1@36 {
				compatible = "mediatek,camera_main";
				reg = <0x36>;
			};
		};

		spi@1100c000 {
			compatible = "mediatek,mt8167-spi";
			#address-cells = <0x1>;
			#size-cells = <0x0>;
			reg = <0x0 0x1100c000 0x0 0x1000>;
			interrupts = <0x0 0x68 0x8>;
			clocks = <0x5 0x1d 0x5 0xc8 0x5 0x59>;
			clock-names = "parent-clk", "sel-clk", "spi-clk";
			status = "disabled";
		};

		thermal@1100d000 {
			compatible = "mediatek,mt8167-thermal";
			reg = <0x0 0x1100d000 0x0 0x1000>;
			interrupts = <0x0 0x4d 0x8>;
			clocks = <0x5 0x43 0x5 0x5f>;
			clock-names = "therm", "auxadc";
			auxadc = <0x29>;
			apmixedsys = <0x6>;
			infracfg = <0x4>;
		};

		ptp_od@1100d000 {
			compatible = "mediatek,mt8167-ptp_od";
			reg = <0x0 0x1100d000 0x0 0x1000>;
			interrupts = <0x0 0x53 0x8>;
			vproc-supply = <0x8>;
			vcore-supply = <0x2a>;
		};

		btif@1100e000 {
			compatible = "mediatek,btif";
			reg = <0x0 0x1100e000 0x0 0x1000>;
			interrupts = <0x0 0x6b 0x8>;
			clocks = <0x5 0x4e 0x5 0x44>;
			clock-names = "btifc", "apdmac";
		};

		disp_pwm0@1100f000 {
			compatible = "mediatek,mt8167-disp_pwm";
			reg = <0x0 0x1100f000 0x0 0x1000>;
		};

		usb@11100000 {
			compatible = "mediatek,mt8167-usb20";
			reg = <0x0 0x11100000 0x0 0x10000 0x0 0x11110000 0x0 0x10000>;
			interrupts = <0x0 0x48 0x8>;
			mode = <0x2>;
			multipoint = <0x1>;
			dyn_fifo = <0x1>;
			soft_con = <0x1>;
			dma = <0x1>;
			num_eps = <0x10>;
			dma_channels = <0x8>;
			iddig_gpio = <0x12 0x29 0x2>;
			clocks = <0x5 0x28 0x5 0x78 0x5 0x4f 0x5 0x6e>;
			clock-names = "usbpll", "usbmcu", "usb", "icusb";
			pinctrl-names = "iddig_irq_init", "drvvbus_init", "drvvbus_low", "drvvbus_high";
			pinctrl-0 = <0x2b>;
			pinctrl-1 = <0x2c>;
			pinctrl-2 = <0x2d>;
			pinctrl-3 = <0x2e>;
			usb-power-supply = <0x2f>;
			status = "okay";
			drvvbus_gpio = <0x12 0x44 0x0>;
		};

		audio-controller@11140000 {
			compatible = "mediatek,mt8167-afe-pcm";
			reg = <0x0 0x11140000 0x0 0x1000 0x0 0x11141000 0x0 0x9000>;
			interrupts = <0x0 0x78 0x8>;
			clocks = <0x5 0x5b 0x5 0x95 0x5 0x96 0x5 0x97 0x5 0x98 0x5 0x99 0x5 0x9a 0x5 0x9b 0x5 0x9c 0x5 0x9d 0x5 0x8a 0x5 0x86 0x5 0x87 0x5 0x84 0x5 0x85 0x5 0xc0 0x5 0xc1 0x5 0xc2 0x5 0xc3 0x5 0xc4 0x5 0xc5 0x5 0xc6>;
			clock-names = "top_pdn_audio", "apll12_div0", "apll12_div1", "apll12_div2", "apll12_div3", "apll12_div4", "apll12_div4b", "apll12_div5", "apll12_div5b", "apll12_div6", "spdif_in", "engen1", "engen2", "aud1", "aud2", "i2s0_m_sel", "i2s1_m_sel", "i2s2_m_sel", "i2s3_m_sel", "i2s4_m_sel", "i2s5_m_sel", "spdif_b_sel";
			assigned-clocks = <0x5 0xbb 0x5 0xbc 0x5 0xbd 0x5 0xbe>;
			assigned-clock-parents = <0x5 0x29 0x5 0x2d 0x5 0x91 0x5 0x94>;
			mediatek,tdm-out-mode = <0x0>;
			linux,phandle = <0x67>;
			phandle = <0x67>;
		};

		clark@13000000 {
			compatible = "mediatek,mt8167-clark";
			reg = <0x0 0x13000000 0x0 0x80000 0x0 0x13ffe000 0x0 0x1000>;
			interrupts = <0x0 0xb9 0x8>;
			interrupt-names = "RGX";
			power-domains = <0x30 0x5>;
			clocks = <0x5 0xae 0x5 0xb9 0x5 0xba 0x5 0x83 0x5 0x82 0x5 0x3e 0x5 0x31 0x5 0x1e 0x5 0xc 0x5 0xa2>;
			clock-names = "mfg_mm_in_sel", "mfg_axi_in_sel", "mfg_slow_in_sel", "top_slow", "top_axi", "top_mm", "slow_clk26m", "bus_univpll_d24", "bus_mainpll_d11", "engine_csw_mux";
			clock-frequency = <0x17d78400>;
		};

		mfgcfg@13ffe000 {
			compatible = "mediatek,mt8167-mfgcfg", "syscon";
			reg = <0x0 0x13ffe000 0x0 0x1000>;
			#clock-cells = <0x1>;
		};

		mmc@11120000 {
			compatible = "mediatek,mt8167-mmc";
			reg = <0x0 0x11120000 0x0 0x1000>;
			interrupts = <0x0 0x4e 0x8>;
			clocks = <0x5 0x53 0x5 0xa1 0x5 0xd9>;
			clock-names = "source", "hclk", "source_cg";
			status = "okay";
			pinctrl-names = "default", "state_uhs";
			pinctrl-0 = <0x31>;
			pinctrl-1 = <0x32>;
			bus-width = <0x8>;
			max-frequency = <0xbebc200>;
			cap-mmc-highspeed;
			mmc-hs200-1_8v;
			cap-mmc-hw-reset;
			vmmc-supply = <0x33>;
			vqmmc-supply = <0x34>;
			non-removable;
		};

		mmc@11130000 {
			compatible = "mediatek,mt8167-mmc";
			reg = <0x0 0x11130000 0x0 0x1000>;
			interrupts = <0x0 0x4f 0x8>;
			clocks = <0x5 0x54 0x5 0xa1 0x5 0xda>;
			clock-names = "source", "hclk", "source_cg";
			status = "okay";
			pinctrl-names = "default", "state_uhs";
			pinctrl-0 = <0x35>;
			pinctrl-1 = <0x36>;
			bus-width = <0x4>;
			max-frequency = <0xbebc200>;
			cap-sd-highspeed;
			sd-uhs-sdr50;
			sd-uhs-sdr104;
			cd-gpios = <0x12 0x14 0x0>;
			vmmc-supply = <0x37>;
			vqmmc-supply = <0x38>;
		};

		audiotop@11140000 {
			compatible = "mediatek,mt8167-audiotop", "syscon";
			reg = <0x0 0x11140000 0x0 0x1000>;
			#clock-cells = <0x1>;
		};

		sdio@11170000 {
			compatible = "mediatek,mt8167-sdio";
			reg = <0x0 0x11170000 0x0 0x1000>;
			interrupts = <0x0 0x6d 0x8>;
			clocks = <0x5 0x61 0x5 0xdb>;
			clock-names = "sdio-bus", "sdio-src";
			status = "okay";
			pinctrl-names = "default";
			pinctrl-0 = <0x39>;
			clk_src = <0x2>;
			host_function = <0x2>;
			bus-width = <0x4>;
			max-frequency = <0xbebc200>;
			cap-sd-highspeed;
			sd-uhs-sdr12;
			sd-uhs-sdr25;
			sd-uhs-sdr50;
			sd-uhs-sdr104;
		};

		usb@11190000 {
			compatible = "mediatek,mt8167-usb11";
			cell-index = <0x1>;
			reg = <0x0 0x11190000 0x0 0x10000 0x0 0x11110000 0x0 0x10000>;
			interrupts = <0x0 0xd2 0x8>;
			mode = <0x2>;
			multipoint = <0x1>;
			dyn_fifo = <0x1>;
			soft_con = <0x1>;
			dma = <0x1>;
			num_eps = <0x8>;
			dma_channels = <0x4>;
			pinctrl-names = "vbus_init", "vbus_low", "vbus_high", "iddig_irq";
			pinctrl-0 = <0x3a>;
			pinctrl-1 = <0x3b>;
			pinctrl-2 = <0x3c>;
			pinctrl-3 = <0x3d>;
			status = "okay";
			vubs_gpio = <0x12 0x18 0x0>;
			iddig_gpio = <0x12 0x28 0x0>;
		};

		mmsys@14000000 {
			compatible = "mediatek,mt8167-mmsys", "syscon";
			reg = <0x0 0x14000000 0x0 0x1000>;
			#clock-cells = <0x1>;
			linux,phandle = <0x16>;
			phandle = <0x16>;
		};

		mdp_rdma@14001000 {
			compatible = "mediatek,mt8167-mdp_rdma";
			reg = <0x0 0x14001000 0x0 0x1000>;
			interrupts = <0x0 0x9a 0x8>;
		};

		mdp_rsz0@14002000 {
			compatible = "mediatek,mt8167-mdp_rsz0";
			reg = <0x0 0x14002000 0x0 0x1000>;
			interrupts = <0x0 0x9b 0x8>;
		};

		mdp_rsz1@14003000 {
			compatible = "mediatek,mt8167-mdp_rsz1";
			reg = <0x0 0x14003000 0x0 0x1000>;
			interrupts = <0x0 0x9c 0x8>;
		};

		mdp_wdma@14004000 {
			compatible = "mediatek,mt8167-mdp_wdma";
			reg = <0x0 0x14004000 0x0 0x1000>;
			interrupts = <0x0 0x9e 0x8>;
		};

		mdp_wrot@14005000 {
			compatible = "mediatek,mt8167-mdp_wrot";
			reg = <0x0 0x14005000 0x0 0x1000>;
			interrupts = <0x0 0x9f 0x8>;
		};

		mdp_tdshp@14006000 {
			compatible = "mediatek,mdp_tdshp";
			reg = <0x0 0x14006000 0x0 0x1000>;
			interrupts = <0x0 0x9d 0x8>;
		};

		mt8167-dispsys {
			compatible = "mediatek,mt8167-dispsys";
			mediatek,larb = <0x13>;
			clocks = <0x16 0x9 0x16 0xa 0x16 0xb 0x16 0xc 0x16 0xd 0x16 0xe 0x16 0xf 0x16 0x10 0x16 0x11 0x16 0x12 0x16 0x13 0x5 0x3c 0x16 0x14 0x16 0x15 0x16 0x16 0x16 0x17 0x16 0x19 0x16 0x18 0x16 0x1a 0x16 0x1b 0x16 0x1d 0x16 0x1c 0x5 0x33 0x5 0x40 0x5 0x80 0x5 0xb7 0x6 0x7 0x5 0x25 0x5 0x26 0x5 0x27 0x5 0x81 0x5 0xb8 0x6 0x6 0x5 0x35 0x5 0x36 0x5 0x37 0x5 0x38 0x5 0xc7 0x5 0x1d>;
			clock-names = "MMSYS_CLK_FAKE_ENG", "MMSYS_CLK_DISP_OVL0", "MMSYS_CLK_DISP_RDMA0", "MMSYS_CLK_DISP_RDMA1", "MMSYS_CLK_DISP_WDMA0", "MMSYS_CLK_DISP_COLOR", "MMSYS_CLK_DISP_CCORR", "MMSYS_CLK_DISP_AAL", "MMSYS_CLK_DISP_GAMMA", "MMSYS_CLK_DISP_DITHER", "MMSYS_CLK_DISP_UFOE", "MMSYS_CLK_TOP_PWM_MM", "MMSYS_CLK_DISP_PWM", "MMSYS_CLK_DISP_PWM26M", "MMSYS_CLK_DSI_ENGINE", "MMSYS_CLK_DSI_DIGITAL", "MMSYS_CLK_DPI0_PIXEL", "MMSYS_CLK_DPI0_ENGINE", "MMSYS_CLK_LVDS_PIXEL", "MMSYS_CLK_LVDS_CTS", "MMSYS_CLK_DPI1_PIXEL", "MMSYS_CLK_DPI1_ENGINE", "MMSYS_CLK_TOP_MIPI_26M", "MMSYS_CLK_TOP_MIPI_26M_DBG", "MMSYS_CLK_TOP_RG_FDPI0", "MMSYS_CLK_MUX_DPI0_SEL", "MMSYS_APMIXED_LVDSPLL", "MMSYS_CLK_MUX_LVDSPLL_D2", "MMSYS_CLK_MUX_LVDSPLL_D4", "MMSYS_CLK_MUX_LVDSPLL_D8", "MMSYS_CLK_TOP_RG_FDPI1", "MMSYS_CLK_MUX_DPI1_SEL", "MMSYS_APMIXED_TVDPLL", "MMSYS_CLK_MUX_TVDPLL_D2", "MMSYS_CLK_MUX_TVDPLL_D4", "MMSYS_CLK_MUX_TVDPLL_D8", "MMSYS_CLK_MUX_TVDPLL_D16", "MMSYS_CLK_PWM_SEL", "TOP_UNIVPLL_D12";
			lcm_power_gpio = <0x12 0x42 0x0>;
		};

		disp_ovl0@14007000 {
			compatible = "mediatek,mt8167-disp_ovl0";
			reg = <0x0 0x14007000 0x0 0x1000>;
			interrupts = <0x0 0xa0 0x8>;
		};

		disp_rdma0@14009000 {
			compatible = "mediatek,mt8167-disp_rdma0";
			reg = <0x0 0x14009000 0x0 0x1000>;
			interrupts = <0x0 0xa2 0x8>;
		};

		disp_rdma1@1400a000 {
			compatible = "mediatek,mt8167-disp_rdma1";
			reg = <0x0 0x1400a000 0x0 0x1000>;
			interrupts = <0x0 0xa3 0x8>;
		};

		disp_wdma0@1400b000 {
			compatible = "mediatek,mt8167-disp_wdma0";
			reg = <0x0 0x1400b000 0x0 0x1000>;
			interrupts = <0x0 0xa4 0x8>;
		};

		disp_color@1400c000 {
			compatible = "mediatek,mt8167-disp_color";
			reg = <0x0 0x1400c000 0x0 0x1000>;
			interrupts = <0x0 0xa5 0x8>;
		};

		disp_ccorr@1400d000 {
			compatible = "mediatek,mt8167-disp_ccorr";
			reg = <0x0 0x1400d000 0x0 0x1000>;
			interrupts = <0x0 0xa6 0x8>;
		};

		disp_aal@1400e000 {
			compatible = "mediatek,mt8167-disp_aal";
			reg = <0x0 0x1400e000 0x0 0x1000>;
			interrupts = <0x0 0xa7 0x8>;
		};

		disp_gamma@1400f000 {
			compatible = "mediatek,mt8167-disp_gamma";
			reg = <0x0 0x1400f000 0x0 0x1000>;
			interrupts = <0x0 0xa8 0x8>;
		};

		disp_dither@14010000 {
			compatible = "mediatek,mt8167-disp_dither";
			reg = <0x0 0x14010000 0x0 0x1000>;
			interrupts = <0x0 0xa9 0x8>;
		};

		disp_dsi0@14012000 {
			compatible = "mediatek,mt8167-disp_dsi0";
			reg = <0x0 0x14012000 0x0 0x1000>;
			interrupts = <0x0 0xab 0x8>;
		};

		disp_dpi0@14013000 {
			compatible = "mediatek,mt8167-disp_dpi0";
			reg = <0x0 0x14013000 0x0 0x1000>;
			interrupts = <0x0 0xac 0x8>;
		};

		mm_mutex@14015000 {
			compatible = "mediatek,mt8167-disp_mutex";
			reg = <0x0 0x14015000 0x0 0x1000>;
			interrupts = <0x0 0x99 0x8>;
		};

		mipi_dphy@14018000 {
			compatible = "mediatek,mt8167-disp_mipi_tx";
			reg = <0x0 0x14018000 0x0 0x90>;
		};

		disp_lvds_ana@14018800 {
			compatible = "mediatek,mt8167-disp_lvds_ana";
			reg = <0x0 0x14018800 0x0 0x1c>;
		};

		disp_dpi1@14019000 {
			compatible = "mediatek,mt8167-disp_dpi1";
			reg = <0x0 0x14019000 0x0 0x1000>;
			interrupts = <0x0 0xae 0x8>;
		};

		disp_lvds_tx@1401a200 {
			compatible = "mediatek,mt8167-disp_lvds_tx";
			reg = <0x0 0x1401a200 0x0 0x64>;
		};

		hdmi@1401b000 {
			compatible = "mediatek,mt8167-hdmitx";
			power-domains = <0x30 0x0>;
			reg = <0x0 0x1401b000 0x0 0x1000 0x0 0x11011000 0x0 0x10 0x0 0x1001a000 0x0 0xbc>;
			interrupts = <0x0 0x94 0x8>;
			clocks = <0x5 0x70 0x5 0x71 0x5 0x72 0x16 0x1e 0x16 0x21 0x16 0x20 0x16 0x1f>;
			clock-names = "clk_ddc", "clk_cec_26m", "clk_cec_32k", "mmsys_hdmi_pixel", "mmsys_hdmi_pll", "mmsys_hdmi_audio", "mmsys_hdmi_spidif";
			status = "okay";
			pinctrl-names = "default", "hdmi_hpd";
			pinctrl-0 = <0x3e>;
			pinctrl-1 = <0x3f>;
		};

		g3d_iommu@13005000 {
			cell-index = <0x2>;
			compatible = "mediatek,mt8167-g3d_iommu";
			reg = <0x0 0x13005000 0x0 0x1000>;
			interrupts = <0x0 0xe2 0x8>;
		};

		larb@14016000 {
			compatible = "mediatek,mt8167-smi-larb";
			reg = <0x0 0x14016000 0x0 0x1000>;
			mediatek,smi = <0x40>;
			mediatek,larbid = <0x0>;
			clocks = <0x16 0x1 0x16 0x1>;
			clock-names = "apb", "smi";
			power-domains = <0x30 0x0>;
			linux,phandle = <0x13>;
			phandle = <0x13>;
		};

		smi@14017000 {
			compatible = "mediatek,mt8167-smi-common";
			reg = <0x0 0x14017000 0x0 0x1000>;
			clocks = <0x16 0x0 0x16 0x0>;
			clock-names = "apb", "smi";
			power-domains = <0x30 0x0>;
			linux,phandle = <0x40>;
			phandle = <0x40>;
		};

		met_smi@14017000 {
			compatible = "mediatek,met_smi";
			reg = <0x0 0x14017000 0x0 0x1000 0x0 0x14016000 0x0 0x1000 0x0 0x15001000 0x0 0x1000 0x0 0x16010000 0x0 0x1000>;
			clocks = <0x16 0x0 0x16 0x1 0x41 0x0 0x42 0x0>;
			clock-names = "smi-common", "smi-larb0", "img-larb1", "vdec-larb2";
		};

		imgsys@15000000 {
			compatible = "mediatek,mt8167-imgsys", "syscon";
			reg = <0x0 0x15000000 0x0 0x1000>;
			#clock-cells = <0x1>;
			linux,phandle = <0x41>;
			phandle = <0x41>;
		};

		isp_display {
			compatible = "mediatek,mt8167-isp_display";
		};

		ispsys@15000000 {
			compatible = "mediatek,mt8167-ispsys";
			reg = <0x0 0x15004000 0x0 0x9000 0x0 0x15000000 0x0 0x10000 0x0 0x10011000 0x0 0x3000>;
			interrupts = <0x0 0xb4 0x8 0x0 0xb7 0x8>;
			clocks = <0x41 0x0 0x41 0x1 0x41 0x2 0x41 0x3 0x41 0x4 0x16 0x0>;
			clock-names = "IMG_LARB_SMI", "IMG_CAM_SMI", "IMG_CAM_CAM", "IMG_SEN_TG", "IMG_SEN_CAM", "MM_SMI_COMMON";
			mediatek,smilarb = <0x14>;
		};

		vencsys@15000000 {
			status = "disabled";
			compatible = "mediatek,mt8167-vencsys", "syscon";
			reg = <0x0 0x15000000 0x0 0x1000>;
			#clock-cells = <0x1>;
		};

		larb@15001000 {
			compatible = "mediatek,mt8167-smi-larb";
			reg = <0x0 0x15001000 0x0 0x10000>;
			mediatek,smi = <0x40>;
			mediatek,larbid = <0x1>;
			clocks = <0x41 0x0 0x41 0x0>;
			clock-names = "apb", "smi";
			power-domains = <0x30 0x2>;
			linux,phandle = <0x14>;
			phandle = <0x14>;
		};

		camera1@15008000 {
			compatible = "mediatek,mt8167-camera_hw";
			reg = <0x0 0x15008000 0x0 0x1000>;
			clocks = <0x5 0xa4 0x5 0x40 0x5 0x3d 0x5 0x28 0x5 0x1c>;
			clock-names = "TOP_CAMTG_SEL", "TOP_CAM_MIPI_26M", "TOP_CAMTG", "TOP_CAM_TG_48M", "TOP_CAM_TG_208M";
			reg-vcama-supply = <0x43>;
			reg-vcamd-supply = <0x44>;
			reg-vcamio-supply = <0x45>;
			reg-vcamaf-supply = <0x46>;
			pinctrl-names = "default", "cam_mclk", "cam_pclk", "cam_gpio90", "cam_gpio91", "cam_gpio92", "cam_gpio93", "cam_gpio94", "cam_gpio95", "cam_gpio96", "cam_gpio97", "cam_gpio98", "cam_gpio99";
			pinctrl-0 = <0x47>;
			pinctrl-1 = <0x48>;
			pinctrl-2 = <0x49>;
			pinctrl-3 = <0x4a>;
			pinctrl-4 = <0x4b>;
			pinctrl-5 = <0x4c>;
			pinctrl-6 = <0x4d>;
			pinctrl-7 = <0x4e>;
			pinctrl-8 = <0x4f>;
			pinctrl-9 = <0x50>;
			pinctrl-10 = <0x51>;
			pinctrl-11 = <0x52>;
			pinctrl-12 = <0x53>;
			cam0_rst = <0x12 0x31 0x0>;
			cam0_pdn = <0x12 0x30 0x0>;
			cam1_rst = <0x12 0x32 0x0>;
			cam1_pdn = <0x12 0x33 0x0>;
			status = "okay";
		};

		camera2@15008000 {
			compatible = "mediatek,mt8167-camera_hw2";
			reg = <0x0 0x15008000 0x0 0x1000>;
			reg-vcama-supply = <0x43>;
			reg-vcamd-supply = <0x44>;
			reg-vcamio-supply = <0x45>;
			reg-vcamaf-supply = <0x46>;
		};

		venc@15009000 {
			compatible = "mediatek,mt8167-venc";
			reg = <0x0 0x15009000 0x0 0x1000>;
			interrupts = <0x0 0xb3 0x8>;
			clocks = <0x41 0x5>;
			clock-names = "img_venc";
		};

		vdecsys@16000000 {
			compatible = "mediatek,mt8167-vdecsys", "syscon";
			reg = <0x0 0x16000000 0x0 0x1000>;
			#clock-cells = <0x1>;
			linux,phandle = <0x42>;
			phandle = <0x42>;
		};

		vdec_gcon@16000000 {
			compatible = "mediatek,mt8167-vdec_gcon";
			reg = <0x0 0x16000000 0x0 0x10000>;
			clocks = <0x42 0x0 0x42 0x1>;
			clock-names = "apb", "smi";
		};

		larb@16010000 {
			compatible = "mediatek,mt8167-smi-larb";
			reg = <0x0 0x16010000 0x0 0x1000>;
			mediatek,smi = <0x40>;
			mediatek,larbid = <0x2>;
			clocks = <0x42 0x0 0x42 0x1>;
			clock-names = "apb", "smi";
			power-domains = <0x30 0x1>;
			linux,phandle = <0x15>;
			phandle = <0x15>;
		};

		vdec@16020000 {
			compatible = "mediatek,mt8167-vdec";
			reg = <0x0 0x16020000 0x0 0x10000>;
			clocks = <0x5 0xb6 0x5 0x18>;
			clock-names = "vdec_sel", "normal";
			interrupts = <0x0 0xb8 0x8>;
		};

		consys@18070000 {
			compatible = "mediatek,mt8167-consys";
			reg = <0x0 0x18070000 0x0 0x200 0x0 0x10000000 0x0 0x2000>;
			power-domains = <0x30 0x6>;
			interrupts = <0x0 0xc3 0x8 0x0 0xc5 0x8>;
			resets = <0x54 0xc>;
			reset-names = "connsys";
			status = "okay";
			pinctrl-names = "default", "gps_lna_state_init", "gps_lna_state_oh", "gps_lna_state_ol";
			pinctrl-0 = <0x55>;
			pinctrl-1 = <0x56>;
			pinctrl-2 = <0x57>;
			pinctrl-3 = <0x58>;
			vcn18-supply = <0x59>;
			vcn35-supply = <0x5a>;
		};

		wifi@180f0000 {
			compatible = "mediatek,wifi";
			reg = <0x0 0x180f0000 0x0 0x5c>;
			interrupts = <0x0 0xc4 0x8>;
			clocks = <0x5 0x44>;
			clock-names = "wifi-dma";
		};

		touch@ {
			compatible = "mediatek,mt8167-touch", "mediatek,mt8163-touch";
			vtouch-supply = <0x5b>;
			tpd-resolution = <0x320 0x500>;
			use-tpd-button = <0x0>;
			tpd-key-num = <0x3>;
			tpd-key-local = <0x8b 0xac 0x9e 0x0>;
			tpd-key-dim-local = <0x5a 0x373 0x64 0x28 0xe6 0x373 0x64 0x28 0x172 0x373 0x64 0x28 0x0 0x0 0x0 0x0>;
			tpd-max-touch-num = <0x5>;
			tpd-filter-enable = <0x1>;
			tpd-filter-pixel-density = <0x7c>;
			tpd-filter-custom-prameters = <0x0 0x0 0x0 0x0 0x0 0x0 0x0 0x0 0x0 0x0 0x0 0x0>;
			tpd-filter-custom-speed = <0x0 0x0 0x0>;
			pinctrl-names = "default", "state_eint_as_int", "state_eint_output0", "state_eint_output1", "state_rst_output0", "state_rst_output1";
			pinctrl-0 = <0x5c>;
			pinctrl-1 = <0x5d>;
			pinctrl-2 = <0x5e>;
			pinctrl-3 = <0x5f>;
			pinctrl-4 = <0x60>;
			pinctrl-5 = <0x61>;
			status = "okay";
		};

		gps {
			compatible = "mediatek,gps";
		};

		hwmsensor@0 {
			compatible = "mediatek,hwmsensor";
		};

		gsensor@0 {
			compatible = "mediatek,gsensor";
		};

		als_ps@0 {
			compatible = "mediatek,als_ps";
		};

		batchsensor@0 {
			compatible = "mediatek,batchsensor";
		};

		gyroscope@0 {
			compatible = "mediatek,gyroscope";
		};

		barometer@0 {
			compatible = "mediatek,barometer";
		};

		msensor@0 {
			compatible = "mediatek,msensor";
		};

		orientation@0 {
			compatible = "mediatek,orientation";
		};

		led@0 {
			compatible = "mediatek,red";
			led_mode = <0x2>;
			data;
			pwm_config = <0x0 0x0 0x0 0x0 0x0>;
			led_gpios_red = <0x12 0x38 0x0 0x12 0x40 0x0>;
		};

		led@1 {
			compatible = "mediatek,green";
			led_mode = <0x2>;
			data;
			pwm_config = <0x0 0x0 0x0 0x0 0x0>;
			led_gpios_green = <0x12 0x37 0x0 0x12 0x41 0x0>;
		};

		led@2 {
			compatible = "mediatek,blue";
			led_mode = <0x6>;
			data = <0x2>;
			pwm_config = <0x0 0x0 0x0 0x0 0x0>;
		};

		led@3 {
			compatible = "mediatek,jogball-backlight";
			led_mode = <0x0>;
			data;
			pwm_config = <0x0 0x0 0x0 0x0 0x0>;
		};

		led@4 {
			compatible = "mediatek,keyboard-backlight";
			led_mode = <0x0>;
			data;
			pwm_config = <0x0 0x0 0x0 0x0 0x0>;
		};

		led@5 {
			compatible = "mediatek,button-backlight";
			led_mode = <0x0>;
			data;
			pwm_config = <0x0 0x0 0x0 0x0 0x0>;
		};

		led@6 {
			compatible = "mediatek,lcd-backlight";
			led_mode = <0x5>;
			data;
			pwm_config = <0x0 0x0 0x0 0x0 0x0>;
		};

		mtkfb@0 {
			compatible = "mediatek,MTKFB";
			mediatek,larb = <0x13>;
		};

		bat_meter {
			compatible = "mediatek,bat_meter";
			r_bat_sense = <0x4>;
			r_i_sense = <0x4>;
			r_charger_1 = <0x14a>;
			r_charger_2 = <0x27>;
			temperature_t0 = <0x6e>;
			temperature_t1 = <0x0>;
			temperature_t2 = <0x19>;
			temperature_t3 = <0x32>;
			temperature_t = <0xff>;
			fg_meter_resistance = <0x0>;
			q_max_pos_50 = <0x1906>;
			q_max_pos_25 = <0x1947>;
			q_max_pos_0 = <0x1945>;
			q_max_neg_10 = <0x18a6>;
			q_max_pos_50_h_current = <0x18d9>;
			q_max_pos_25_h_current = <0x191f>;
			q_max_pos_0_h_current = <0x1922>;
			q_max_neg_10_h_current = <0x17dd>;
			oam_d5 = <0x1>;
			change_tracking_point = <0x1>;
			cust_tracking_point = <0xe>;
			cust_r_sense = <0xc8>;
			cust_hw_cc = <0x0>;
			aging_tuning_value = <0x64>;
			cust_r_fg_offset = <0x0>;
			ocv_board_compesate = <0x0>;
			r_fg_board_base = <0x3e8>;
			r_fg_board_slope = <0x3e8>;
			car_tune_value = <0x59>;
			current_detect_r_fg = <0xa>;
			minerroroffset = <0x3e8>;
			fg_vbat_average_size = <0x12>;
			r_fg_value = <0xa>;
			cust_poweron_delta_capacity_tolrance = <0x50>;
			cust_poweron_low_capacity_tolrance = <0x2>;
			cust_poweron_max_vbat_tolrance = <0x46>;
			cust_poweron_delta_vbat_tolrance = <0x3c>;
			cust_poweron_delta_hw_sw_ocv_capacity_tolrance = <0xa>;
			fixed_tbat_25 = <0x0>;
			vbat_normal_wakeup = <0xe10>;
			vbat_low_power_wakeup = <0xdac>;
			normal_wakeup_period = <0x1518>;
			low_power_wakeup_period = <0x12c>;
			close_poweroff_wakeup_period = <0x1e>;
			rbat_pull_up_r = <0x4204>;
			rbat_pull_up_volt = <0x708>;
			batt_temperature_table_num = <0x11>;
			batt_temperature_table = <0xffffffec 0x113fe 0xfffffff1 0xd829 0xfffffff6 0xaa8e 0xfffffffb 0x8788 0x0 0x6c70 0x5 0x5756 0xa 0x46c9 0xf 0x39ba 0x14 0x2f5a 0x19 0x2710 0x1e 0x2067 0x23 0x1b04 0x28 0x16a4 0x2d 0x1311 0x32 0x1022 0x37 0xdb6 0x3c 0xbb5>;
			batt_temperature_table_tcl = <0xffffffec 0x11c72 0xfffffff1 0xdd0b 0xfffffff6 0xad51 0xfffffffb 0x890d 0x0 0x6d3d 0x5 0x57bb 0xa 0x46f7 0xf 0x39cb 0x14 0x2f5e 0x19 0x2710 0x1e 0x2067 0x23 0x1b06 0x28 0x16a9 0x2d 0x1318 0x32 0x102b 0x37 0xdc0 0x3c 0xbbf>;
			battery_profile_t0_num = <0x5e>;
			battery_profile_t0 = <0x0 0x1049 0x1 0x1038 0x2 0x1028 0x3 0x1013 0x4 0xffe 0x5 0xff2 0x6 0xfe7 0x7 0xfd8 0x9 0xfc7 0xa 0xfb6 0xb 0xfa8 0xc 0xf9d 0xd 0xf93 0xe 0xf8b 0xf 0xf85 0x10 0xf7f 0x11 0xf79 0x12 0xf75 0x13 0xf71 0x14 0xf6e 0x15 0xf68 0x16 0xf63 0x18 0xf5d 0x19 0xf57 0x1a 0xf51 0x1b 0xf4a 0x1c 0xf42 0x1d 0xf3b 0x1e 0xf33 0x1f 0xf2d 0x20 0xf24 0x21 0xf1e 0x22 0xf17 0x23 0xf11 0x24 0xf0a 0x25 0xf05 0x26 0xf01 0x28 0xefb 0x29 0xef7 0x2a 0xef3 0x2b 0xeef 0x2c 0xeeb 0x2d 0xee8 0x2e 0xee5 0x2f 0xee1 0x30 0xede 0x31 0xedb 0x32 0xed9 0x33 0xed6 0x34 0xed3 0x35 0xed1 0x36 0xece 0x38 0xecc 0x39 0xecb 0x3a 0xec9 0x3b 0xec6 0x3c 0xec5 0x3d 0xec4 0x3e 0xec3 0x3f 0xec2 0x40 0xec1 0x41 0xebf 0x43 0xebd 0x45 0xeba 0x47 0xeb7 0x48 0xeb5 0x49 0xeb3 0x4a 0xeb1 0x4b 0xeae 0x4c 0xea9 0x4e 0xea5 0x4f 0xea2 0x50 0xe9f 0x51 0xe9a 0x52 0xe96 0x53 0xe93 0x54 0xe8d 0x55 0xe88 0x57 0xe83 0x58 0xe7e 0x59 0xe7b 0x5a 0xe78 0x5b 0xe76 0x5c 0xe71 0x5d 0xe6e 0x5e 0xe67 0x5f 0xe5c 0x60 0xe49 0x61 0xe2c 0x62 0xe05 0x63 0xdd3 0x64 0xd90 0x64 0xd2e 0x64 0xc52>;
			battery_profile_t0_tcl = <0x0 0x104c 0x1 0x1040 0x2 0x1036 0x3 0x102c 0x4 0x1020 0x5 0x1016 0x6 0x100d 0x7 0x1002 0x8 0xffa 0x9 0xff0 0xb 0xfe8 0xc 0xfe2 0xd 0xfd7 0xe 0xfce 0xf 0xfc3 0x10 0xfbb 0x11 0xfb0 0x12 0xfa6 0x13 0xf9d 0x14 0xf95 0x15 0xf8c 0x16 0xf86 0x17 0xf7c 0x18 0xf76 0x19 0xf6f 0x1a 0xf66 0x1b 0xf5f 0x1c 0xf57 0x1d 0xf51 0x1f 0xf48 0x20 0xf40 0x21 0xf37 0x22 0xf32 0x23 0xf29 0x24 0xf24 0x25 0xf1d 0x26 0xf15 0x27 0xf11 0x28 0xf09 0x2a 0xf00 0x2b 0xef9 0x2c 0xef5 0x2d 0xef2 0x2e 0xeed 0x2f 0xee9 0x30 0xee5 0x31 0xee1 0x33 0xede 0x34 0xedb 0x35 0xed8 0x36 0xed4 0x37 0xed2 0x38 0xece 0x39 0xecc 0x3a 0xec8 0x3b 0xec6 0x3c 0xec4 0x3d 0xec3 0x3e 0xebf 0x3f 0xebd 0x40 0xebb 0x41 0xeba 0x42 0xeb8 0x43 0xeb6 0x44 0xeb3 0x47 0xeb1 0x48 0xead 0x49 0xeab 0x4a 0xea9 0x4b 0xea6 0x4c 0xea3 0x4d 0xea0 0x4e 0xe99 0x4f 0xe9a 0x50 0xe97 0x51 0xe93 0x52 0xe8d 0x53 0xe87 0x54 0xe84 0x55 0xe7e 0x56 0xe79 0x57 0xe74 0x58 0xe70 0x5a 0xe6d 0x5b 0xe6a 0x5c 0xe66 0x5d 0xe65 0x5e 0xe61 0x5f 0xe5a 0x60 0xe4f 0x61 0xe3c 0x62 0xe19 0x63 0xdeb 0x64 0xda9>;
			battery_profile_t1_num = <0x5e>;
			battery_profile_t1 = <0x0 0x1049 0x1 0x1038 0x2 0x102c 0x3 0x1021 0x4 0x1017 0x5 0x100e 0x6 0x1006 0x7 0x1001 0x8 0xffc 0xa 0xfec 0xc 0xfd2 0xd 0xfc3 0xf 0xfac 0x11 0xf9b 0x12 0xf95 0x13 0xf8f 0x14 0xf8b 0x16 0xf82 0x18 0xf79 0x19 0xf74 0x1a 0xf6f 0x1b 0xf6a 0x1c 0xf64 0x1d 0xf5e 0x1e 0xf58 0x1f 0xf53 0x20 0xf4c 0x21 0xf46 0x22 0xf3f 0x23 0xf37 0x24 0xf2f 0x25 0xf27 0x26 0xf20 0x27 0xf19 0x28 0xf12 0x29 0xf0c 0x2a 0xf07 0x2b 0xf03 0x2c 0xefe 0x2d 0xefa 0x2e 0xef7 0x2f 0xef3 0x30 0xeef 0x31 0xeed 0x32 0xee9 0x33 0xee6 0x34 0xee4 0x35 0xee1 0x36 0xedf 0x37 0xedd 0x39 0xed8 0x3a 0xed6 0x3b 0xed5 0x3c 0xed3 0x3e 0xed0 0x40 0xece 0x41 0xecd 0x42 0xecc 0x43 0xecc 0x44 0xeca 0x45 0xec9 0x46 0xec8 0x47 0xec7 0x48 0xec5 0x49 0xec3 0x4b 0xebe 0x4c 0xebc 0x4d 0xeb8 0x4e 0xeb6 0x4f 0xeb3 0x50 0xeb0 0x51 0xead 0x52 0xea9 0x53 0xea5 0x54 0xea0 0x55 0xe9c 0x56 0xe98 0x57 0xe93 0x58 0xe8d 0x59 0xe86 0x5a 0xe80 0x5b 0xe7d 0x5c 0xe7b 0x5d 0xe79 0x5e 0xe77 0x5f 0xe73 0x60 0xe6d 0x61 0xe5a 0x62 0xe37 0x63 0xe0a 0x64 0xdd0 0x64 0xd83 0x64 0xd10 0x64 0xc4a>;
			battery_profile_t1_tcl = <0x0 0x1050 0x1 0x1042 0x2 0x1037 0x3 0x102b 0x4 0x101f 0x5 0x1015 0x6 0x100b 0x7 0x1002 0x8 0xff8 0x9 0xfef 0xa 0xfe6 0xb 0xfde 0xd 0xfd7 0xe 0xfcc 0xf 0xfc2 0x10 0xfbb 0x11 0xfb1 0x12 0xfa8 0x13 0xfa0 0x14 0xf98 0x15 0xf91 0x16 0xf89 0x17 0xf82 0x18 0xf7c 0x19 0xf76 0x1a 0xf70 0x1b 0xf69 0x1c 0xf63 0x1d 0xf5c 0x1e 0xf56 0x1f 0xf50 0x20 0xf49 0x21 0xf43 0x22 0xf3c 0x24 0xf36 0x25 0xf2f 0x26 0xf28 0x27 0xf21 0x28 0xf18 0x29 0xf11 0x2a 0xf09 0x2b 0xf03 0x2c 0xefd 0x2d 0xef7 0x2e 0xef3 0x2f 0xeed 0x30 0xee7 0x31 0xee3 0x32 0xee0 0x33 0xedc 0x34 0xed8 0x35 0xed5 0x36 0xed2 0x37 0xecf 0x38 0xecd 0x39 0xecb 0x3b 0xec8 0x3c 0xec5 0x3d 0xec4 0x3e 0xec3 0x3f 0xec1 0x40 0xebe 0x41 0xebd 0x42 0xebd 0x43 0xebb 0x44 0xeba 0x47 0xeb8 0x48 0xeb6 0x49 0xeb4 0x4a 0xeb2 0x4c 0xead 0x4d 0xeab 0x4e 0xea8 0x4f 0xea5 0x50 0xea2 0x51 0xe9d 0x53 0xe99 0x54 0xe93 0x55 0xe8d 0x56 0xe86 0x57 0xe81 0x58 0xe79 0x59 0xe70 0x5a 0xe69 0x5b 0xe66 0x5c 0xe64 0x5d 0xe62 0x5e 0xe5e 0x5f 0xe5a 0x60 0xe52 0x61 0xe42 0x62 0xe19 0x63 0xde2 0x64 0xd97>;
			battery_profile_t2_num = <0x5e>;
			battery_profile_t2 = <0x0 0x105a 0x1 0x1049 0x2 0x103f 0x4 0x102c 0x6 0x1019 0x8 0x1008 0x9 0xfff 0xa 0xff7 0xb 0xfe9 0xd 0xfdc 0xe 0xfd2 0xf 0xfc6 0x10 0xfbb 0x11 0xfb1 0x12 0xfa8 0x13 0xfa1 0x14 0xf9a 0x15 0xf94 0x18 0xf84 0x19 0xf7e 0x1b 0xf73 0x1c 0xf6d 0x1d 0xf67 0x1e 0xf62 0x1f 0xf5c 0x20 0xf51 0x21 0xf4b 0x22 0xf45 0x23 0xf3f 0x24 0xf39 0x26 0xf2b 0x27 0xf22 0x28 0xf19 0x29 0xf11 0x2a 0xf0a 0x2b 0xf04 0x2c 0xeff 0x2d 0xefa 0x2e 0xef6 0x2f 0xef1 0x30 0xeee 0x31 0xeea 0x32 0xee7 0x33 0xee3 0x34 0xee1 0x35 0xedb 0x36 0xed8 0x37 0xed6 0x38 0xed3 0x39 0xed1 0x3a 0xecf 0x3b 0xecd 0x3c 0xecb 0x3d 0xec9 0x3e 0xec7 0x3f 0xec6 0x40 0xec4 0x41 0xec3 0x42 0xec1 0x43 0xec0 0x44 0xebf 0x45 0xebe 0x46 0xebc 0x47 0xeba 0x48 0xeb6 0x49 0xeb0 0x4a 0xead 0x4b 0xeaa 0x4c 0xea6 0x4d 0xea3 0x4f 0xe9e 0x50 0xe9b 0x51 0xe98 0x52 0xe95 0x53 0xe91 0x54 0xe8d 0x55 0xe88 0x56 0xe84 0x57 0xe80 0x58 0xe7b 0x59 0xe75 0x5a 0xe6d 0x5b 0xe6a 0x5d 0xe67 0x5e 0xe62 0x5f 0xe5e 0x60 0xe52 0x61 0xe35 0x62 0xe0f 0x63 0xdde 0x64 0xd9e 0x64 0xd48 0x64 0xcba 0x64 0xc51>;
			battery_profile_t2_tcl = <0x0 0x1059 0x1 0x104f 0x2 0x1044 0x3 0x103a 0x4 0x1030 0x5 0x1027 0x6 0x101f 0x7 0x1016 0x8 0x100c 0x9 0x1003 0xa 0xffc 0xb 0xff3 0xc 0xfea 0xd 0xfe3 0xe 0xfda 0xf 0xfd4 0x10 0xfca 0x11 0xfc2 0x12 0xfbb 0x13 0xfb4 0x14 0xfac 0x15 0xfa6 0x16 0xf9e 0x17 0xf98 0x18 0xf8a 0x19 0xf84 0x1a 0xf7e 0x1b 0xf78 0x1c 0xf72 0x1d 0xf6c 0x1e 0xf66 0x1f 0xf61 0x20 0xf5b 0x21 0xf56 0x22 0xf51 0x23 0xf4b 0x24 0xf46 0x25 0xf40 0x26 0xf3b 0x27 0xf34 0x28 0xf2c 0x29 0xf24 0x2a 0xf1a 0x2b 0xf11 0x2c 0xf0a 0x2d 0xf02 0x2e 0xefc 0x2f 0xef8 0x30 0xef4 0x32 0xeed 0x33 0xee8 0x35 0xee3 0x36 0xee0 0x37 0xedd 0x38 0xeda 0x39 0xed8 0x3a 0xed5 0x3b 0xed2 0x3c 0xed0 0x3e 0xecd 0x3f 0xeca 0x41 0xec7 0x42 0xec4 0x44 0xec2 0x45 0xebf 0x47 0xebc 0x48 0xeb8 0x49 0xeb5 0x4a 0xeb2 0x4b 0xeaf 0x4c 0xeab 0x4d 0xea8 0x4e 0xea4 0x4f 0xea0 0x50 0xe9c 0x51 0xe99 0x52 0xe94 0x53 0xe8e 0x54 0xe88 0x55 0xe81 0x56 0xe7d 0x57 0xe77 0x58 0xe6e 0x59 0xe66 0x5a 0xe63 0x5b 0xe60 0x5d 0xe5e 0x5e 0xe5c 0x5f 0xe5a 0x60 0xe53 0x61 0xe41 0x62 0xe1e 0x63 0xdef 0x64 0xd63>;
			battery_profile_t3_num = <0x5e>;
			battery_profile_t3 = <0x0 0x1053 0x1 0x1045 0x2 0x1037 0x3 0x102e 0x4 0x1025 0x5 0x101b 0x6 0x1010 0x7 0x1007 0x8 0xffe 0x9 0xff5 0xa 0xfe3 0xb 0xfda 0xd 0xfc9 0xe 0xfc1 0xf 0xfba 0x10 0xfb0 0x11 0xfa8 0x13 0xf9b 0x14 0xf91 0x15 0xf8a 0x17 0xf7c 0x19 0xf6e 0x1a 0xf67 0x1c 0xf5b 0x1d 0xf53 0x1f 0xf47 0x20 0xf3c 0x21 0xf36 0x22 0xf31 0x23 0xf29 0x24 0xf25 0x25 0xf1f 0x26 0xf18 0x27 0xf14 0x28 0xf0c 0x29 0xf01 0x2a 0xef9 0x2b 0xef0 0x2c 0xee8 0x2d 0xee2 0x2e 0xedd 0x2f 0xed9 0x30 0xed6 0x31 0xed1 0x32 0xecb 0x33 0xec6 0x34 0xec3 0x35 0xec0 0x36 0xebc 0x37 0xeba 0x38 0xeb8 0x39 0xeb5 0x3a 0xeb4 0x3b 0xeb1 0x3c 0xeaf 0x3d 0xead 0x3e 0xeaa 0x40 0xea7 0x41 0xea4 0x43 0xea1 0x44 0xe9f 0x45 0xe9c 0x46 0xe99 0x47 0xe95 0x48 0xe90 0x49 0xe8a 0x4a 0xe87 0x4b 0xe80 0x4c 0xe7d 0x4d 0xe7a 0x4e 0xe77 0x4f 0xe74 0x50 0xe71 0x51 0xe6f 0x52 0xe6c 0x53 0xe69 0x54 0xe66 0x55 0xe60 0x57 0xe58 0x58 0xe53 0x59 0xe4a 0x5a 0xe42 0x5b 0xe3e 0x5d 0xe3b 0x5f 0xe38 0x60 0xe31 0x61 0xe25 0x62 0xe06 0x63 0xddf 0x64 0xdaf 0x64 0xd71 0x64 0xd1e 0x64 0xc9b 0x64 0xc6a>;
			battery_profile_t3_tcl = <0x0 0x104b 0x1 0x1040 0x2 0x1036 0x3 0x102c 0x4 0x1023 0x5 0x1018 0x6 0x100f 0x7 0x1005 0x8 0xffd 0x9 0xff5 0xa 0xfec 0xb 0xfe4 0xc 0xfdb 0xd 0xfd2 0xe 0xfca 0xf 0xfc3 0x10 0xfbb 0x11 0xfb3 0x12 0xfab 0x13 0xfa4 0x14 0xf9c 0x15 0xf94 0x16 0xf8d 0x17 0xf87 0x18 0xf80 0x19 0xf79 0x1a 0xf71 0x1b 0xf6c 0x1c 0xf66 0x1d 0xf60 0x1e 0xf5a 0x1f 0xf53 0x20 0xf4d 0x21 0xf48 0x22 0xf43 0x23 0xf3d 0x24 0xf37 0x25 0xf33 0x26 0xf2e 0x27 0xf27 0x28 0xf22 0x29 0xf1c 0x2a 0xf15 0x2b 0xf0b 0x2c 0xf02 0x2d 0xef9 0x2e 0xef1 0x2f 0xeeb 0x31 0xee4 0x32 0xee0 0x33 0xedc 0x34 0xed8 0x35 0xed5 0x36 0xed1 0x37 0xece 0x38 0xecb 0x39 0xec8 0x3a 0xec5 0x3b 0xec3 0x3c 0xec0 0x3e 0xebc 0x3f 0xeba 0x40 0xeb7 0x41 0xeb5 0x42 0xeb3 0x43 0xeb1 0x44 0xeaf 0x45 0xead 0x46 0xeaa 0x47 0xea8 0x48 0xea5 0x49 0xe9e 0x4a 0xe97 0x4c 0xe91 0x4d 0xe8d 0x4e 0xe8a 0x4f 0xe82 0x51 0xe7c 0x53 0xe73 0x54 0xe6d 0x55 0xe67 0x56 0xe60 0x57 0xe5c 0x58 0xe55 0x59 0xe4d 0x5a 0xe48 0x5c 0xe45 0x5e 0xe42 0x5f 0xe3d 0x60 0xe38 0x61 0xe24 0x62 0xe00 0x63 0xdd0 0x64 0xd97>;
			r_profile_t0_num = <0x5e>;
			r_profile_t0 = <0xb0 0x1049 0xb0 0x1038 0xb5 0x1028 0xbd 0x1013 0xcd 0xffe 0xdb 0xff2 0xe0 0xfe7 0xe4 0xfd8 0xe6 0xfc7 0xe7 0xfb6 0xe8 0xfa8 0xea 0xf9d 0xeb 0xf93 0xed 0xf8b 0xed 0xf85 0xf0 0xf7f 0xef 0xf79 0xf1 0xf75 0xf3 0xf71 0xf7 0xf6e 0xe4 0xf68 0xf7 0xf63 0xf6 0xf5d 0xf8 0xf57 0xf7 0xf51 0xf7 0xf4a 0xf5 0xf42 0xf6 0xf3b 0xf2 0xf33 0xf0 0xf2d 0xee 0xf24 0xed 0xf1e 0xed 0xf17 0xec 0xf11 0xc6 0xf0a 0xe7 0xf05 0xea 0xf01 0xe9 0xefb 0xe9 0xef7 0xec 0xef3 0xed 0xeef 0xec 0xeeb 0xed 0xee8 0xee 0xee5 0xee 0xee1 0xef 0xede 0xf0 0xedb 0xf0 0xed9 0xf1 0xed6 0xf1 0xed3 0xf2 0xed1 0xf3 0xece 0xf4 0xecc 0xf6 0xecb 0xf7 0xec9 0xf6 0xec6 0xf7 0xec5 0xf7 0xec4 0xf8 0xec3 0xf9 0xec2 0xf9 0xec1 0xfb 0xebf 0xfd 0xebd 0xfc 0xeba 0xfb 0xeb7 0xfe 0xeb5 0xff 0xeb3 0xfe 0xeb1 0xff 0xeae 0xff 0xea9 0x101 0xea5 0x102 0xea2 0x103 0xe9f 0x104 0xe9a 0x103 0xe96 0x106 0xe93 0x107 0xe8d 0x107 0xe88 0x10a 0xe83 0x10b 0xe7e 0x111 0xe7b 0x116 0xe78 0x120 0xe76 0x127 0xe71 0x135 0xe6e 0x142 0xe67 0x154 0xe5c 0x168 0xe49 0x182 0xe2c 0x1ab 0xe05 0x1e8 0xdd3 0x248 0xd90 0x253 0xd2e 0x232 0xc52>;
			r_profile_t0_tcl = <0xa9 0x104c 0xa9 0x1040 0xad 0x1036 0xb0 0x102c 0xb0 0x1020 0xb2 0x1016 0xb8 0x100d 0xb7 0x1002 0xbb 0xffa 0xbc 0xff0 0xbf 0xfe8 0xc2 0xfe2 0xc1 0xfd7 0xc2 0xfce 0xc0 0xfc3 0xc5 0xfbb 0xc6 0xfb0 0xc5 0xfa6 0xc6 0xf9d 0xc9 0xf95 0xc6 0xf8c 0xc9 0xf86 0xc6 0xf7c 0xc7 0xf76 0xc7 0xf6f 0xc4 0xf66 0xc3 0xf5f 0xc4 0xf57 0xc3 0xf51 0xbe 0xf48 0xbd 0xf40 0xb8 0xf37 0xbd 0xf32 0xb8 0xf29 0xb7 0xf24 0xb5 0xf1d 0xb0 0xf15 0xb5 0xf11 0xb0 0xf09 0xb0 0xf00 0xb0 0xef9 0xae 0xef5 0xb2 0xef2 0xb2 0xeed 0xb4 0xee9 0xb1 0xee5 0xb2 0xee1 0xb5 0xede 0xb4 0xedb 0xb6 0xed8 0xb6 0xed4 0xb9 0xed2 0xb6 0xece 0xb8 0xecc 0xb8 0xec8 0xb9 0xec6 0xb9 0xec4 0xbd 0xec3 0xba 0xebf 0xba 0xebd 0xba 0xebb 0xbc 0xeba 0xbb 0xeb8 0xbc 0xeb6 0xbe 0xeb3 0xbf 0xeb1 0xbc 0xead 0xbd 0xeab 0xbd 0xea9 0xbf 0xea6 0xbe 0xea3 0xbd 0xea0 0xbc 0xe99 0xac 0xe9a 0xc0 0xe97 0xc4 0xe93 0xc2 0xe8d 0xc0 0xe87 0xc2 0xe84 0xbc 0xe7e 0xbc 0xe79 0xbb 0xe74 0xbd 0xe70 0xbd 0xe6d 0xc1 0xe6a 0xc8 0xe66 0xca 0xe65 0xe1 0xe61 0xf0 0xe5a 0x100 0xe4f 0x10e 0xe3c 0x11d 0xe19 0x14a 0xdeb 0x1a3 0xda9>;
			r_profile_t1_num = <0x5e>;
			r_profile_t1 = <0x7a 0x1049 0x7a 0x1038 0x7c 0x102c 0x7c 0x1021 0x7e 0x1017 0x7f 0x100e 0x80 0x1006 0x82 0x1001 0x83 0xffc 0x83 0xfec 0x84 0xfd2 0x85 0xfc3 0x85 0xfac 0x88 0xf9b 0x88 0xf95 0x89 0xf8f 0x8b 0xf8b 0x8a 0xf82 0x8f 0xf79 0x90 0xf74 0x90 0xf6f 0x92 0xf6a 0x92 0xf64 0x92 0xf5e 0x93 0xf58 0x93 0xf53 0x91 0xf4c 0x90 0xf46 0x90 0xf3f 0x8e 0xf37 0x8b 0xf2f 0x89 0xf27 0x87 0xf20 0x86 0xf19 0x84 0xf12 0x83 0xf0c 0x81 0xf07 0x7f 0xf03 0x7f 0xefe 0x7e 0xefa 0x81 0xef7 0x81 0xef3 0x80 0xeef 0x81 0xeed 0x81 0xee9 0x82 0xee6 0x83 0xee4 0x83 0xee1 0x80 0xedf 0x81 0xedd 0x84 0xed8 0x85 0xed6 0x85 0xed5 0x86 0xed3 0x86 0xed0 0x87 0xece 0x86 0xecd 0x86 0xecc 0x86 0xecc 0x88 0xeca 0x88 0xec9 0x88 0xec8 0x88 0xec7 0x88 0xec5 0x89 0xec3 0x88 0xebe 0x86 0xebc 0x84 0xeb8 0x85 0xeb6 0x88 0xeb3 0x88 0xeb0 0x88 0xead 0x88 0xea9 0x89 0xea5 0x89 0xea0 0x8a 0xe9c 0x8a 0xe98 0x8b 0xe93 0x8a 0xe8d 0x87 0xe86 0x89 0xe80 0x8b 0xe7d 0x8d 0xe7b 0x90 0xe79 0x96 0xe77 0x9c 0xe73 0xa4 0xe6d 0xa5 0xe5a 0xa7 0xe37 0xae 0xe0a 0xc1 0xdd0 0xec 0xd83 0x14f 0xd10 0x18a 0xc4a>;
			r_profile_t1_tcl = <0x72 0x1050 0x72 0x1042 0x73 0x1037 0x72 0x102b 0x73 0x101f 0x77 0x1015 0x73 0x100b 0x77 0x1002 0x77 0xff8 0x79 0xfef 0x7a 0xfe6 0x7c 0xfde 0x7d 0xfd7 0x7c 0xfcc 0x7c 0xfc2 0x82 0xfbb 0x80 0xfb1 0x84 0xfa8 0x86 0xfa0 0x84 0xf98 0x88 0xf91 0x87 0xf89 0x88 0xf82 0x8a 0xf7c 0x8b 0xf76 0x8d 0xf70 0x8f 0xf69 0x8e 0xf63 0x8e 0xf5c 0x90 0xf56 0x90 0xf50 0x8f 0xf49 0x8e 0xf43 0x8d 0xf3c 0x8e 0xf36 0x8c 0xf2f 0x89 0xf28 0x88 0xf21 0x84 0xf18 0x81 0xf11 0x7d 0xf09 0x7c 0xf03 0x7a 0xefd 0x79 0xef7 0x7a 0xef3 0x78 0xeed 0x74 0xee7 0x74 0xee3 0x77 0xee0 0x76 0xedc 0x74 0xed8 0x76 0xed5 0x75 0xed2 0x75 0xecf 0x78 0xecd 0x77 0xecb 0x75 0xec8 0x75 0xec5 0x7a 0xec4 0x7a 0xec3 0x7a 0xec1 0x78 0xebe 0x7a 0xebd 0x7d 0xebd 0x7c 0xebb 0x7c 0xeba 0x7e 0xeb8 0x7c 0xeb6 0x7e 0xeb4 0x7c 0xeb2 0x7d 0xead 0x7e 0xeab 0x7c 0xea8 0x7e 0xea5 0x7e 0xea2 0x7d 0xe9d 0x7e 0xe99 0x7c 0xe93 0x7c 0xe8d 0x7d 0xe86 0x7f 0xe81 0x7d 0xe79 0x7b 0xe70 0x78 0xe69 0x7a 0xe66 0x7d 0xe64 0x7f 0xe62 0x85 0xe5e 0x8d 0xe5a 0x9a 0xe52 0x9f 0xe42 0x9a 0xe19 0xa5 0xde2 0xbc 0xd97>;
			r_profile_t2_num = <0x5e>;
			r_profile_t2 = <0x54 0x105a 0x54 0x1049 0x55 0x103f 0x56 0x102c 0x56 0x1019 0x57 0x1008 0x57 0xfff 0x58 0xff7 0x59 0xfe9 0x59 0xfdc 0x59 0xfd2 0x58 0xfc6 0x58 0xfbb 0x59 0xfb1 0x59 0xfa8 0x59 0xfa1 0x59 0xf9a 0x59 0xf94 0x5b 0xf84 0x5b 0xf7e 0x5c 0xf73 0x5c 0xf6d 0x5c 0xf67 0x5d 0xf62 0x5d 0xf5c 0x5e 0xf51 0x60 0xf4b 0x60 0xf45 0x61 0xf3f 0x62 0xf39 0x5f 0xf2b 0x5d 0xf22 0x5b 0xf19 0x59 0xf11 0x57 0xf0a 0x58 0xf04 0x57 0xeff 0x57 0xefa 0x56 0xef6 0x56 0xef1 0x57 0xeee 0x57 0xeea 0x56 0xee7 0x56 0xee3 0x57 0xee1 0x57 0xedb 0x57 0xed8 0x57 0xed6 0x57 0xed3 0x57 0xed1 0x57 0xecf 0x57 0xecd 0x57 0xecb 0x58 0xec9 0x58 0xec7 0x59 0xec6 0x59 0xec4 0x5a 0xec3 0x59 0xec1 0x5a 0xec0 0x5b 0xebf 0x5b 0xebe 0x5a 0xebc 0x59 0xeba 0x58 0xeb6 0x57 0xeb0 0x57 0xead 0x57 0xeaa 0x57 0xea6 0x56 0xea3 0x58 0xe9e 0x57 0xe9b 0x57 0xe98 0x58 0xe95 0x57 0xe91 0x58 0xe8d 0x58 0xe88 0x58 0xe84 0x59 0xe80 0x59 0xe7b 0x59 0xe75 0x58 0xe6d 0x58 0xe6a 0x5a 0xe67 0x5c 0xe62 0x5d 0xe5e 0x5c 0xe52 0x5c 0xe35 0x5d 0xe0f 0x60 0xdde 0x63 0xd9e 0x6c 0xd48 0x84 0xcba 0xed 0xc51>;
			r_profile_t2_tcl = <0x57 0x1059 0x57 0x104f 0x57 0x1044 0x58 0x103a 0x56 0x1030 0x57 0x1027 0x5a 0x101f 0x5a 0x1016 0x58 0x100c 0x56 0x1003 0x5b 0xffc 0x59 0xff3 0x57 0xfea 0x5b 0xfe3 0x5a 0xfda 0x5d 0xfd4 0x5a 0xfca 0x5a 0xfc2 0x5b 0xfbb 0x5c 0xfb4 0x5c 0xfac 0x5e 0xfa6 0x5e 0xf9e 0x5e 0xf98 0x5f 0xf8a 0x5e 0xf84 0x61 0xf7e 0x61 0xf78 0x61 0xf72 0x64 0xf6c 0x65 0xf66 0x67 0xf61 0x67 0xf5b 0x68 0xf56 0x6a 0xf51 0x69 0xf4b 0x6c 0xf46 0x6c 0xf40 0x6e 0xf3b 0x6e 0xf34 0x6b 0xf2c 0x6a 0xf24 0x62 0xf1a 0x5f 0xf11 0x5e 0xf0a 0x5a 0xf02 0x58 0xefc 0x5a 0xef8 0x5c 0xef4 0x5b 0xeed 0x59 0xee8 0x5a 0xee3 0x5b 0xee0 0x5a 0xedd 0x5a 0xeda 0x5b 0xed8 0x5a 0xed5 0x5b 0xed2 0x5b 0xed0 0x60 0xecd 0x5f 0xeca 0x5f 0xec7 0x5f 0xec4 0x5e 0xec2 0x5e 0xebf 0x5f 0xebc 0x5e 0xeb8 0x5e 0xeb5 0x5c 0xeb2 0x5b 0xeaf 0x5b 0xeab 0x5d 0xea8 0x5d 0xea4 0x5b 0xea0 0x5b 0xe9c 0x5c 0xe99 0x5b 0xe94 0x5a 0xe8e 0x5c 0xe88 0x5a 0xe81 0x5d 0xe7d 0x5b 0xe77 0x5b 0xe6e 0x59 0xe66 0x58 0xe63 0x59 0xe60 0x5e 0xe5e 0x61 0xe5c 0x65 0xe5a 0x65 0xe53 0x62 0xe41 0x62 0xe1e 0x65 0xdef 0x6a 0xd63>;
			r_profile_t3_num = <0x5e>;
			r_profile_t3 = <0x51 0x1053 0x51 0x1045 0x4c 0x1037 0x4f 0x102e 0x51 0x1025 0x51 0x101b 0x4f 0x1010 0x51 0x1007 0x4f 0xffe 0x4f 0xff5 0x51 0xfe3 0x4f 0xfda 0x4f 0xfc9 0x51 0xfc1 0x51 0xfba 0x4f 0xfb0 0x4f 0xfa8 0x54 0xf9b 0x51 0xf91 0x4f 0xf8a 0x51 0xf7c 0x51 0xf6e 0x51 0xf67 0x54 0xf5b 0x51 0xf53 0x51 0xf47 0x56 0xf3c 0x56 0xf36 0x56 0xf31 0x54 0xf29 0x56 0xf25 0x56 0xf1f 0x56 0xf18 0x58 0xf14 0x58 0xf0c 0x54 0xf01 0x53 0xef9 0x51 0xef0 0x4f 0xee8 0x4f 0xee2 0x4f 0xedd 0x51 0xed9 0x51 0xed6 0x51 0xed1 0x51 0xecb 0x4f 0xec6 0x4f 0xec3 0x4f 0xec0 0x4f 0xebc 0x4c 0xeba 0x4f 0xeb8 0x51 0xeb5 0x51 0xeb4 0x51 0xeb1 0x51 0xeaf 0x54 0xead 0x51 0xeaa 0x54 0xea7 0x51 0xea4 0x51 0xea1 0x51 0xe9f 0x53 0xe9c 0x51 0xe99 0x51 0xe95 0x51 0xe90 0x51 0xe8a 0x51 0xe87 0x4f 0xe80 0x4f 0xe7d 0x4f 0xe7a 0x4f 0xe77 0x4f 0xe74 0x51 0xe71 0x51 0xe6f 0x51 0xe6c 0x51 0xe69 0x51 0xe66 0x4f 0xe60 0x4f 0xe58 0x4f 0xe53 0x54 0xe4a 0x51 0xe42 0x4f 0xe3e 0x4f 0xe3b 0x54 0xe38 0x56 0xe31 0x56 0xe25 0x54 0xe06 0x56 0xddf 0x56 0xdaf 0x5b 0xd71 0x62 0xd1e 0x77 0xc9b 0x8d 0xc6a>;
			r_profile_t3_tcl = <0x52 0x104b 0x52 0x1040 0x54 0x1036 0x54 0x102c 0x55 0x1023 0x52 0x1018 0x53 0x100f 0x51 0x1005 0x54 0xffd 0x53 0xff5 0x52 0xfec 0x53 0xfe4 0x54 0xfdb 0x54 0xfd2 0x52 0xfca 0x54 0xfc3 0x55 0xfbb 0x54 0xfb3 0x55 0xfab 0x56 0xfa4 0x55 0xf9c 0x55 0xf94 0x54 0xf8d 0x58 0xf87 0x58 0xf80 0x56 0xf79 0x55 0xf71 0x57 0xf6c 0x57 0xf66 0x59 0xf60 0x5a 0xf5a 0x58 0xf53 0x57 0xf4d 0x58 0xf48 0x5b 0xf43 0x5a 0xf3d 0x5c 0xf37 0x5c 0xf33 0x5f 0xf2e 0x5e 0xf27 0x5f 0xf22 0x5f 0xf1c 0x61 0xf15 0x5d 0xf0b 0x5b 0xf02 0x57 0xef9 0x55 0xef1 0x54 0xeeb 0x56 0xee4 0x56 0xee0 0x54 0xedc 0x56 0xed8 0x55 0xed5 0x54 0xed1 0x54 0xece 0x54 0xecb 0x55 0xec8 0x56 0xec5 0x55 0xec3 0x57 0xec0 0x57 0xebc 0x5a 0xeba 0x58 0xeb7 0x57 0xeb5 0x58 0xeb3 0x58 0xeb1 0x59 0xeaf 0x59 0xead 0x58 0xeaa 0x59 0xea8 0x59 0xea5 0x55 0xe9e 0x54 0xe97 0x54 0xe91 0x54 0xe8d 0x54 0xe8a 0x53 0xe82 0x56 0xe7c 0x54 0xe73 0x54 0xe6d 0x55 0xe67 0x52 0xe60 0x56 0xe5c 0x58 0xe55 0x54 0xe4d 0x53 0xe48 0x58 0xe45 0x5c 0xe42 0x5c 0xe3d 0x60 0xe38 0x5b 0xe24 0x5b 0xe00 0x5a 0xdd0 0x5e 0xd97>;
		};

		BAT_NOTIFY {
			compatible = "mediatek,bat_notify";
		};

		bat_comm {
			compatible = "mediatek,battery";
			battery_id = <0x12 0xa 0x0>;
			stop_charging_in_takling = <0x1>;
			talking_recharge_voltage = <0xed8>;
			talking_sync_time = <0x3c>;
			mtk_temperature_recharge_support = <0x1>;
			max_charge_temperature = <0x32>;
			max_charge_temperature_minus_x_degree = <0x2f>;
			min_charge_temperature = <0x0>;
			min_charge_temperature_plus_x_degree = <0x6>;
			err_charge_temperature = <0xff>;
			v_pre2cc_thres = <0xd48>;
			v_cc2topoff_thres = <0xfd2>;
			recharging_voltage = <0x100e>;
			charging_full_current = <0x64>;
			config_usb_if = <0x0>;
			usb_charger_current_suspend = <0x0>;
			usb_charger_current_unconfigured = <0x1b58>;
			usb_charger_current_configured = <0xc350>;
			usb_charger_current = <0xc350>;
			ac_charger_input_current = <0x30d40>;
			ac_charger_current = <0x30d40>;
			non_std_ac_charger_current = <0xc350>;
			charging_host_charger_current = <0xfde8>;
			apple_0_5a_charger_current = <0xc350>;
			apple_1_0a_charger_current = <0xfde8>;
			apple_2_1a_charger_current = <0x13880>;
			bat_low_temp_protect_enable = <0x0>;
			v_charger_enable = <0x0>;
			v_charger_max = <0x1964>;
			v_charger_min = <0x1130>;
			onehundred_percent_tracking_time = <0xa>;
			npercent_tracking_time = <0x14>;
			sync_to_real_tracking_time = <0x3c>;
			v_0percent_tracking = <0xdac>;
			high_battery_voltage_support = <0x0>;
			interrupt-parent = <0x62>;
			interrupts = <0xa 0x4>;
		};

		dumchar {
			compatible = "mediatek,mt8167-dummy_char";
		};

		extd_drv@0 {
			compatible = "mediatek,extd_dev";
		};

		flashlight@ {
			compatible = "mediatek,camera_flashlight";
			pinctrl-names = "default", "hwen_high", "hwen_low";
			pinctrl-0 = <0x55>;
			pinctrl-1 = <0x63>;
			pinctrl-2 = <0x64>;
			status = "okay";
		};

		ice_debug {
			compatible = "mediatek,mt8167-ice_debug", "mediatek,mt8173-ice_debug";
			clocks = <0x5 0x4a>;
			clock-names = "ice_dbg";
		};

		isp_pipemgr {
			compatible = "mediatek,mt8167-isp_pipemgr";
		};

		isp_sysram {
			compatible = "mediatek,mt8167-isp_sysram";
		};

		mfgsys-async {
			compatible = "mediatek,mt8167-mfg-async";
			power-domains = <0x30 0x3>;
		};

		mfgsys-2d {
			compatible = "mediatek,mt8167-mfg-2d";
			power-domains = <0x30 0x4>;
		};

		mtee {
			compatible = "mediatek,mtee";
			clocks = <0x5 0x7b 0x5 0x65 0x41 0x5 0x16 0x0 0x41 0x0>;
			clock-names = "GCPU", "TRNG", "IMG_CLK", "SMI_COMMON", "IMG_SMI";
			pm-devs = <0x14 0x40>;
			pm-names = "isp", "disp";
		};

		mtgpufreq {
			compatible = "mediatek,mt8167-gpufreq";
			reg-vgpu-supply = <0x2a>;
		};

		pseudo-m4u {
			compatible = "mediatek,mt8167-pseudo-m4u";
			iommus = <0x65 0x1>;
		};

		pseudo-m4u-larb0 {
			compatible = "mediatek,mt8167-pseudo-port-m4u";
			mediatek,larbid = <0x0>;
			iommus = <0x65 0x0 0x65 0x1 0x65 0x2 0x65 0x3 0x65 0x4 0x65 0x5 0x65 0x5 0x65 0x6 0x65 0x7>;
		};

		pseudo-m4u-larb1 {
			compatible = "mediatek,mt8167-pseudo-port-m4u";
			mediatek,larbid = <0x1>;
			iommus = <0x65 0x8 0x65 0x9 0x65 0xa 0x65 0xb 0x65 0xc 0x65 0xd 0x65 0xe 0x65 0xf 0x65 0x10 0x65 0x11 0x65 0x12 0x65 0x13 0x65 0x14>;
		};

		pseudo-m4u-larb2 {
			compatible = "mediatek,mt8167-pseudo-port-m4u";
			mediatek,larbid = <0x2>;
			iommus = <0x65 0x15 0x65 0x16 0x65 0x17 0x65 0x18 0x65 0x19 0x65 0x1a 0x65 0x1b>;
		};
	};

	lcm {
		compatible = "mediatek,lcm";
	};

	memory@00000000 {
		device_type = "memory";
		reg = <0x0 0x40000000 0x0 0x20000000>;
	};

	chosen {
		bootargs = "console=ttyS0,921600n1 root=/dev/ram initrd=0x44000200,0x200000";
	};

	cust_accel@0 {
		compatible = "mediatek,lis3dh";
		i2c_num = <0x1>;
		i2c_addr = <0x19 0x0 0x0 0x0>;
		direction = <0x5>;
		power_id = <0xffff>;
		power_vol = <0x0>;
		firlen = <0x10>;
		is_batch_supported = <0x0>;
	};

	fixedregulator@0 {
		compatible = "regulator-fixed";
		regulator-name = "mmc_io";
		regulator-min-microvolt = <0x1b7740>;
		regulator-max-microvolt = <0x1b7740>;
		regulator-always-on;
	};

	fixedregulator@1 {
		compatible = "regulator-fixed";
		regulator-name = "mmc_power";
		regulator-min-microvolt = <0x325aa0>;
		regulator-max-microvolt = <0x325aa0>;
		regulator-always-on;
	};

	mtcpufreq {
		compatible = "mediatek,mt8167-cpufreq";
		reg-ext-vproc-supply = <0x66>;
	};

	mt8167_audio_codec {
		compatible = "mediatek,mt8167-codec";
		clocks = <0x5 0x5b>;
		clock-names = "bus";
		mediatek,afe-regmap = <0x67>;
		mediatek,apmixedsys-regmap = <0x6>;
		mediatek,pwrap-regmap = <0x11>;
		mediatek,speaker-mode = <0x0>;
		mediatek,dmic-wire-mode = <0x1>;
		mediatek,headphone-cap-sel = <0x1>;
	};

	panel@0 {
		compatible = "nt,nt71397_wuxga_dsi_vdo_nt65902";
		reg-lcm-supply = <0x68>;
		status = "okay";
	};

	sound {
		compatible = "mediatek,mt8167-mt6392";
		mediatek,platform = <0x67>;
		mediatek,hp-spk-amp-warmup-time-us = <0x9c40>;
		pinctrl-names = "default", "extamp_on", "extamp_off";
		pinctrl-0 = <0x69>;
		pinctrl-1 = <0x6a>;
		pinctrl-2 = <0x6b>;
		status = "okay";
	};

	vibrator@0 {
		compatible = "mediatek,vibrator";
		vib_timer = <0x19>;
		vib_limit = <0x9>;
		vib_vol = <0x5>;
	};

	mediatek,connectivity-combo {
		compatible = "mediatek,connectivity-combo";
		gpio_combo_pmu_en_pin = <0x12 0x2 0x0>;
		gpio_combo_rst_pin = <0x12 0x7 0x0>;
		gpio_wifi_eint_pin = <0x12 0x5 0x0>;
		gpio_pcm_daiclk_pin = <0x12 0x24 0x0>;
		gpio_pcm_daipcmin_pin = <0x12 0x26 0x0>;
		gpio_pcm_daipcmout_pin = <0x12 0x27 0x0>;
		gpio_pcm_daisync_pin = <0x12 0x25 0x0>;
		gpio_gps_lna_pin = <0x12 0x3 0x0>;
		pinctrl-names = "gpio_pmu_en_pull_dis", "gpio_pmu_en_in_pulldown", "gpio_rst_pull_dis", "gpio_wifi_eint_in_pull_dis", "gpio_wifi_eint_in_pullup", "gpio_pcm_daiclk_pull_dis", "gpio_pcm_daipcmin_pull_dis", "gpio_pcm_daipcmout_pull_dis", "gpio_pcm_daisync_pull_dis", "gpio_gps_lna_pull_dis", "gpio_urxd_uart_pull_dis", "gpio_urxd_gpio_in_pullup", "gpio_urxd_uart_out_low", "gpio_urxd_gpio_in_pull_dis", "gpio_utxd_uart_pull_dis";
		pinctrl-0 = <0x6c>;
		pinctrl-1 = <0x6d>;
		pinctrl-2 = <0x6e>;
		pinctrl-3 = <0x6f>;
		pinctrl-4 = <0x70>;
		pinctrl-5 = <0x71>;
		pinctrl-6 = <0x72>;
		pinctrl-7 = <0x73>;
		pinctrl-8 = <0x74>;
		pinctrl-9 = <0x75>;
		interrupt-parent = <0x12>;
		interrupts = <0x5 0x8>;
		status = "okay";
	};
};
